VERSION ""

NS_ :

BS_:

BU_:

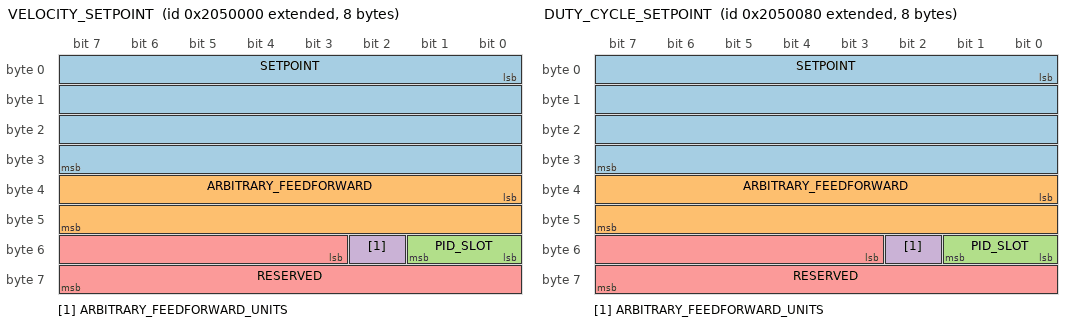
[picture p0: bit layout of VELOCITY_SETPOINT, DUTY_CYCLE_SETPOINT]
BO_ 2181365760 VELOCITY_SETPOINT: 8 Vector__XXX
 SG_ SETPOINT : 0|32@1- (1,0) [0|0] "" Vector__XXX
 SG_ ARBITRARY_FEEDFORWARD : 32|16@1- (0.0009765923,0) [0|0] "" Vector__XXX
 SG_ PID_SLOT : 48|2@1+ (1,0) [0|0] "" Vector__XXX
 SG_ ARBITRARY_FEEDFORWARD_UNITS : 50|1@1+ (1,0) [0|0] "" Vector__XXX
 SG_ RESERVED : 51|13@1+ (1,0) [0|0] "" Vector__XXX

CM_ BO_ 2181365760 "Sets the Control Type to Velocity and sets the target velocity";
CM_ SG_ 2181365760 SETPOINT "By default, the unit is RPM, but it can be changed implicitly using the Velocity Conversion Factor parameter";
CM_ SG_ 2181365760 ARBITRARY_FEEDFORWARD_UNITS "0: Voltage, 1: Duty Cycle (-1 to 1)";
SIG_VALTYPE_ 2181365760 SETPOINT : 1;

BO_ 2181365888 DUTY_CYCLE_SETPOINT: 8 Vector__XXX
 SG_ SETPOINT : 0|32@1- (1,0) [0|0] "" Vector__XXX
 SG_ ARBITRARY_FEEDFORWARD : 32|16@1- (0.0009765923,0) [0|0] "" Vector__XXX
 SG_ PID_SLOT : 48|2@1+ (1,0) [0|0] "" Vector__XXX
 SG_ ARBITRARY_FEEDFORWARD_UNITS : 50|1@1+ (1,0) [0|0] "" Vector__XXX
 SG_ RESERVED : 51|13@1+ (1,0) [0|0] "" Vector__XXX

CM_ BO_ 2181365888 "Sets the Control Type to Duty Cycle and sets the target duty cycle (from -1 to 1)";
CM_ SG_ 2181365888 ARBITRARY_FEEDFORWARD_UNITS "0: Voltage, 1: Duty Cycle (-1 to 1)";
SIG_VALTYPE_ 2181365888 SETPOINT : 1;

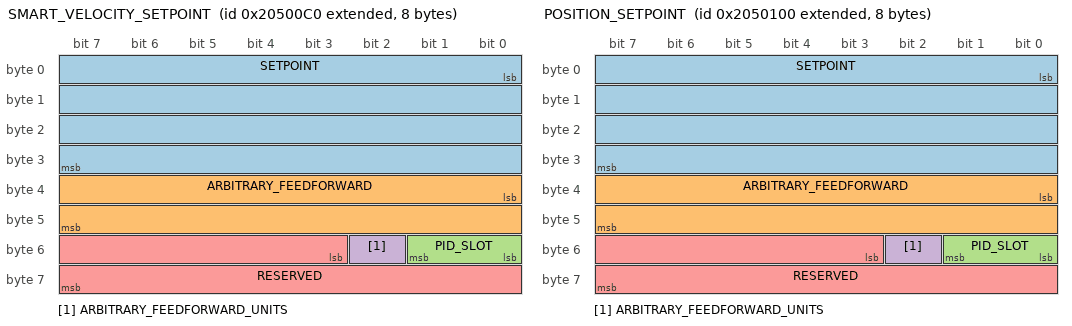
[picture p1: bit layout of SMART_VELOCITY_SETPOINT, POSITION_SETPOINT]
BO_ 2181365952 SMART_VELOCITY_SETPOINT: 8 Vector__XXX
 SG_ SETPOINT : 0|32@1- (1,0) [0|0] "" Vector__XXX
 SG_ ARBITRARY_FEEDFORWARD : 32|16@1- (0.0009765923,0) [0|0] "" Vector__XXX
 SG_ PID_SLOT : 48|2@1+ (1,0) [0|0] "" Vector__XXX
 SG_ ARBITRARY_FEEDFORWARD_UNITS : 50|1@1+ (1,0) [0|0] "" Vector__XXX
 SG_ RESERVED : 51|13@1+ (1,0) [0|0] "" Vector__XXX

CM_ BO_ 2181365952 "Sets the Control Type to Smart Velocity and sets the target velocity";
CM_ SG_ 2181365952 SETPOINT "By default, the unit is RPM, but it can be changed implicitly using the Velocity Conversion Factor parameter";
CM_ SG_ 2181365952 ARBITRARY_FEEDFORWARD_UNITS "0: Voltage, 1: Duty Cycle (-1 to 1)";
SIG_VALTYPE_ 2181365952 SETPOINT : 1;

BO_ 2181366016 POSITION_SETPOINT: 8 Vector__XXX
 SG_ SETPOINT : 0|32@1- (1,0) [0|0] "" Vector__XXX
 SG_ ARBITRARY_FEEDFORWARD : 32|16@1- (0.0009765923,0) [0|0] "" Vector__XXX
 SG_ PID_SLOT : 48|2@1+ (1,0) [0|0] "" Vector__XXX
 SG_ ARBITRARY_FEEDFORWARD_UNITS : 50|1@1+ (1,0) [0|0] "" Vector__XXX
 SG_ RESERVED : 51|13@1+ (1,0) [0|0] "" Vector__XXX

CM_ BO_ 2181366016 "Sets the Control Type to Position and sets the target position";
CM_ SG_ 2181366016 SETPOINT "By default, the unit is rotations, but it can be changed implicitly using the Position Conversion Factor parameter";
CM_ SG_ 2181366016 ARBITRARY_FEEDFORWARD_UNITS "0: Voltage, 1: Duty Cycle (-1 to 1)";
SIG_VALTYPE_ 2181366016 SETPOINT : 1;

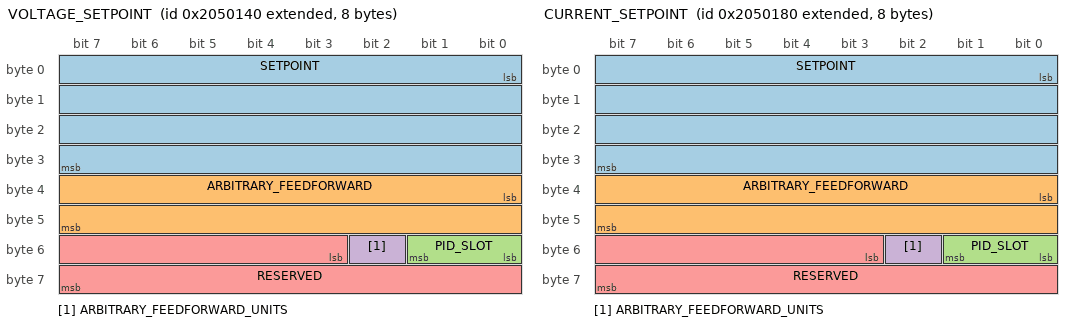
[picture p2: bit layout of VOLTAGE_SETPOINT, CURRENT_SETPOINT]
BO_ 2181366080 VOLTAGE_SETPOINT: 8 Vector__XXX
 SG_ SETPOINT : 0|32@1- (1,0) [0|0] "V" Vector__XXX
 SG_ ARBITRARY_FEEDFORWARD : 32|16@1- (0.0009765923,0) [0|0] "" Vector__XXX
 SG_ PID_SLOT : 48|2@1+ (1,0) [0|0] "" Vector__XXX
 SG_ ARBITRARY_FEEDFORWARD_UNITS : 50|1@1+ (1,0) [0|0] "" Vector__XXX
 SG_ RESERVED : 51|13@1+ (1,0) [0|0] "" Vector__XXX

CM_ BO_ 2181366080 "Sets the Control Type to Voltage and sets the target voltage";
CM_ SG_ 2181366080 ARBITRARY_FEEDFORWARD_UNITS "0: Voltage, 1: Duty Cycle (-1 to 1)";
SIG_VALTYPE_ 2181366080 SETPOINT : 1;

BO_ 2181366144 CURRENT_SETPOINT: 8 Vector__XXX
 SG_ SETPOINT : 0|32@1- (1,0) [0|0] "A" Vector__XXX
 SG_ ARBITRARY_FEEDFORWARD : 32|16@1- (0.0009765923,0) [0|0] "" Vector__XXX
 SG_ PID_SLOT : 48|2@1+ (1,0) [0|0] "" Vector__XXX
 SG_ ARBITRARY_FEEDFORWARD_UNITS : 50|1@1+ (1,0) [0|0] "" Vector__XXX
 SG_ RESERVED : 51|13@1+ (1,0) [0|0] "" Vector__XXX

CM_ BO_ 2181366144 "Sets the Control Type to Current and sets the target current";
CM_ SG_ 2181366144 ARBITRARY_FEEDFORWARD_UNITS "0: Voltage, 1: Duty Cycle (-1 to 1)";
SIG_VALTYPE_ 2181366144 SETPOINT : 1;

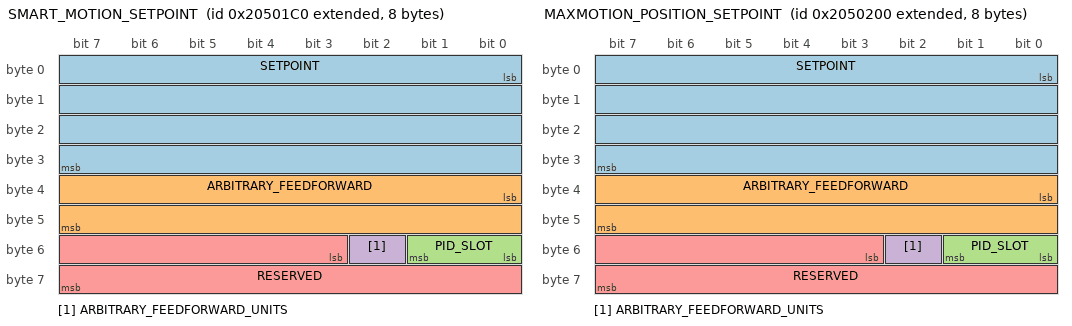
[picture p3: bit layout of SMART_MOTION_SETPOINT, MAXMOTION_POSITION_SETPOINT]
BO_ 2181366208 SMART_MOTION_SETPOINT: 8 Vector__XXX
 SG_ SETPOINT : 0|32@1- (1,0) [0|0] "" Vector__XXX
 SG_ ARBITRARY_FEEDFORWARD : 32|16@1- (0.0009765923,0) [0|0] "" Vector__XXX
 SG_ PID_SLOT : 48|2@1+ (1,0) [0|0] "" Vector__XXX
 SG_ ARBITRARY_FEEDFORWARD_UNITS : 50|1@1+ (1,0) [0|0] "" Vector__XXX
 SG_ RESERVED : 51|13@1+ (1,0) [0|0] "" Vector__XXX

CM_ BO_ 2181366208 "Sets the Control Type to Smart Motion and sets the target position";
CM_ SG_ 2181366208 SETPOINT "By default, the unit is rotations, but it can be changed implicitly using the Position Conversion Factor parameter";
CM_ SG_ 2181366208 ARBITRARY_FEEDFORWARD_UNITS "0: Voltage, 1: Duty Cycle (-1 to 1)";
SIG_VALTYPE_ 2181366208 SETPOINT : 1;

BO_ 2181366272 MAXMOTION_POSITION_SETPOINT: 8 Vector__XXX
 SG_ SETPOINT : 0|32@1- (1,0) [0|0] "" Vector__XXX
 SG_ ARBITRARY_FEEDFORWARD : 32|16@1- (0.0009765923,0) [0|0] "" Vector__XXX
 SG_ PID_SLOT : 48|2@1+ (1,0) [0|0] "" Vector__XXX
 SG_ ARBITRARY_FEEDFORWARD_UNITS : 50|1@1+ (1,0) [0|0] "" Vector__XXX
 SG_ RESERVED : 51|13@1+ (1,0) [0|0] "" Vector__XXX

CM_ BO_ 2181366272 "Sets the Control Type to MAXMotion Position Control and sets the target position";
CM_ SG_ 2181366272 SETPOINT "By default, the unit is rotations, but it can be changed implicitly using the Position Conversion Factor parameter";
CM_ SG_ 2181366272 ARBITRARY_FEEDFORWARD_UNITS "0: Voltage, 1: Duty Cycle (-1 to 1)";
SIG_VALTYPE_ 2181366272 SETPOINT : 1;

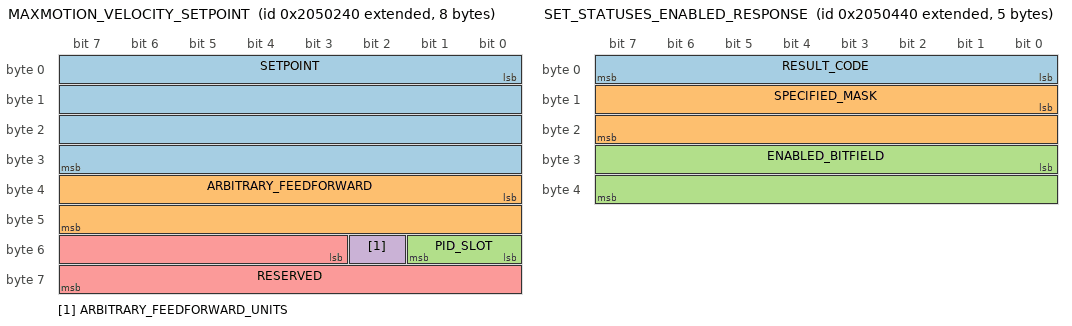
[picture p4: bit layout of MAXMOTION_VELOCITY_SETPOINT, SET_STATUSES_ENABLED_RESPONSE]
BO_ 2181366336 MAXMOTION_VELOCITY_SETPOINT: 8 Vector__XXX
 SG_ SETPOINT : 0|32@1- (1,0) [0|0] "" Vector__XXX
 SG_ ARBITRARY_FEEDFORWARD : 32|16@1- (0.0009765923,0) [0|0] "" Vector__XXX
 SG_ PID_SLOT : 48|2@1+ (1,0) [0|0] "" Vector__XXX
 SG_ ARBITRARY_FEEDFORWARD_UNITS : 50|1@1+ (1,0) [0|0] "" Vector__XXX
 SG_ RESERVED : 51|13@1+ (1,0) [0|0] "" Vector__XXX

CM_ BO_ 2181366336 "Sets the Control Type to MAXMotion Velocity Control and sets the target velocity";
CM_ SG_ 2181366336 SETPOINT "By default, the unit is RPM, but it can be changed implicitly using the Velocity Conversion Factor parameter";
CM_ SG_ 2181366336 ARBITRARY_FEEDFORWARD_UNITS "0: Voltage, 1: Duty Cycle (-1 to 1)";
SIG_VALTYPE_ 2181366336 SETPOINT : 1;

BO_ 2181366784 SET_STATUSES_ENABLED: 4 Vector__XXX
 SG_ MASK : 0|16@1+ (1,0) [0|0] "" Vector__XXX
 SG_ ENABLED_BITFIELD : 16|16@1+ (1,0) [0|0] "" Vector__XXX

CM_ BO_ 2181366784 "Enable or disable status frames. In response, a Set Statuses Enabled Response frame will be sent.";

BO_ 2181366848 SET_STATUSES_ENABLED_RESPONSE: 5 Vector__XXX
 SG_ RESULT_CODE : 0|8@1+ (1,0) [0|0] "" Vector__XXX
 SG_ SPECIFIED_MASK : 8|16@1+ (1,0) [0|0] "" Vector__XXX
 SG_ ENABLED_BITFIELD : 24|16@1+ (1,0) [0|0] "" Vector__XXX

CM_ BO_ 2181366848 "Response for a Set Statuses Enabled command";
CM_ SG_ 2181366848 RESULT_CODE "0 on success, 1 if any non-existent or unavailable frames were specified to be enabled";
CM_ SG_ 2181366848 SPECIFIED_MASK "Contains the mask specified in the Set Statuses Enabled command that triggered this response";
CM_ SG_ 2181366848 ENABLED_BITFIELD "Contains the full bitfield specifying which status frames are currently enabled, without any masking";

BO_ 2181367040 PERSIST_PARAMETERS_RESPONSE: 1 Vector__XXX
 SG_ RESULT_CODE : 0|8@1+ (1,0) [0|0] "" Vector__XXX

CM_ SG_ 2181367040 RESULT_CODE "0 on success";

BO_ 2181367104 RESET_SAFE_PARAMETERS: 2 Vector__XXX
 SG_ MAGIC_NUMBER : 0|16@1+ (1,0) [36292|36292] "" Vector__XXX

CM_ BO_ 2181367104 "Resets most writable parameters to their default values, except CAN ID, Motor Type, Idle Mode, PWM Input Deadband, and Duty Cycle Offset. In response, a Reset Safe Parameters Response frame is sent.";

BO_ 2181367168 RESET_SAFE_PARAMETERS_RESPONSE: 1 Vector__XXX
 SG_ RESULT_CODE : 0|8@1+ (1,0) [0|0] "" Vector__XXX

CM_ BO_ 2181367168 "Response for a Reset Safe Parameters command";
CM_ SG_ 2181367168 RESULT_CODE "0 on success";

BO_ 2181367232 COMPLETE_FACTORY_RESET: 2 Vector__XXX
 SG_ MAGIC_NUMBER : 0|16@1+ (1,0) [29741|29741] "" Vector__XXX

CM_ BO_ 2181367232 "Resets all writable parameters to default values, even CAN ID, Motor Type, Idle Mode, PWM Input Deadband, and Duty Cycle Offset. In response, a Complete Factory Reset Response frame is sent.";

BO_ 2181367296 COMPLETE_FACTORY_RESET_RESPONSE: 1 Vector__XXX
 SG_ RESULT_CODE : 0|8@1+ (1,0) [0|0] "" Vector__XXX

CM_ BO_ 2181367296 "Response for a Complete Factory Reset command";
CM_ SG_ 2181367296 RESULT_CODE "0 on success";

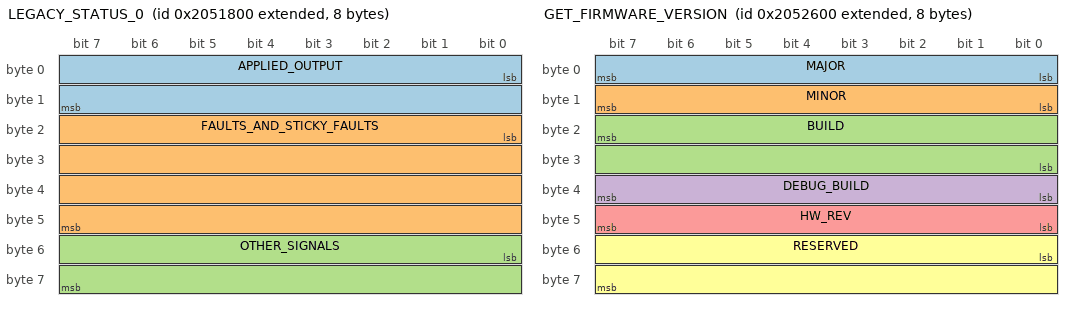
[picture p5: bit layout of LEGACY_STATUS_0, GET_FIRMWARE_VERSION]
BO_ 2181371904 LEGACY_STATUS_0: 8 Vector__XXX
 SG_ APPLIED_OUTPUT : 0|16@1+ (1,0) [0|0] "" Vector__XXX
 SG_ FAULTS_AND_STICKY_FAULTS : 16|32@1+ (1,0) [4294967295|4294967295] "" Vector__XXX
 SG_ OTHER_SIGNALS : 48|16@1+ (1,0) [0|0] "" Vector__XXX

CM_ BO_ 2181371904 "This frame exists purely to inform old software that is not aware of firmware version 25+ that the SPARK is present";
CM_ SG_ 2181371904 APPLIED_OUTPUT "Always 0 so that SPARKs running old firmware trying to follow this SPARK don't move";
CM_ SG_ 2181371904 FAULTS_AND_STICKY_FAULTS "Always has all faults set so that old software knows that something is wrong";
CM_ SG_ 2181371904 OTHER_SIGNALS "The other signals don't matter very much, and all get set to 0";

BO_ 2181372800 CLEAR_FAULTS: 0 Vector__XXX

BO_ 2181373312 IDENTIFY_UNIQUE_SPARK: 4 Vector__XXX
 SG_ UNIQUE_ID : 0|32@1+ (1,0) [0|0] "" Vector__XXX

CM_ BO_ 2181373312 "Makes the specified, single SPARK (even if there are multiple SPARKs that have the same CAN ID) temporarily perform a special blink pattern that will make it stand out";

BO_ 2181373376 IDENTIFY: 0 Vector__XXX

CM_ BO_ 2181373376 "Makes the SPARK temporarily perform a special blink pattern that will make it stand out. Use Identify Unique Device if there may be multiple SPARKs with the same CAN ID.";

BO_ 2181373952 NACK: 0 Vector__XXX

CM_ BO_ 2181373952 "As of SPARK MAX firmware 1.6.3, this is only used as a potential response to setting the CAN ID";

BO_ 2181374016 ACK: 0 Vector__XXX

CM_ BO_ 2181374016 "As of SPARK MAX firmware 1.6.3, this is only used as a potential response to setting the CAN ID";

BO_ 2181375168 LED_SYNC: 0 Vector__XXX

CM_ BO_ 2181375168 "Causes all SPARKs on the bus to synchronize their LED patterns";

BO_ 2181375296 SET_CAN_ID: 5 Vector__XXX
 SG_ UNIQUE_ID : 0|32@1+ (1,0) [0|0] "" Vector__XXX
 SG_ CAN_ID : 32|8@1+ (1,0) [0|63] "" Vector__XXX

CM_ BO_ 2181375296 "Allows changing the CAN ID when multiple devices on the bus currently have the same CAN ID. Under normal circumstances, the CAN ID parameter can be used.";

BO_ 2181375488 GET_FIRMWARE_VERSION: 8 Vector__XXX
 SG_ MAJOR : 0|8@1+ (1,0) [0|0] "" Vector__XXX
 SG_ MINOR : 8|8@1+ (1,0) [0|0] "" Vector__XXX
 SG_ BUILD : 23|16@0+ (1,0) [0|0] "" Vector__XXX
 SG_ DEBUG_BUILD : 32|8@1+ (1,0) [0|0] "" Vector__XXX
 SG_ HW_REV : 40|8@1+ (1,0) [0|0] "" Vector__XXX
 SG_ RESERVED : 48|16@1+ (1,0) [0|0] "" Vector__XXX

BO_ 2181375744 SWDL_DATA: 8 Vector__XXX
 SG_ DATA : 0|64@1+ (1,0) [0|0] "" Vector__XXX

CM_ BO_ 2181375744 "Broadcast from the host to all SPARKs in SWDL mode, containing a slice of firmware data";

BO_ 2181375808 SWDL_CHECKSUM: 8 Vector__XXX
 SG_ CHECKSUM : 0|64@1+ (1,0) [0|0] "" Vector__XXX

CM_ BO_ 2181375808 "Broadcast from the host to all SPARKs in SWDL mode, containing the checksum of the full firmware image that was just sent";

BO_ 2181375872 SWDL_RETRANSMIT: 0 Vector__XXX

CM_ BO_ 2181375872 "Sent by SPARK devices in response to receiving an SWDL Checksum frame that does not match the firmware data they received";

BO_ 2181376000 SET_PRIMARY_ENCODER_POSITION: 5 Vector__XXX
 SG_ POSITION : 0|32@1- (1,0) [0|0] "" Vector__XXX
 SG_ DATA_TYPE : 32|8@1+ (1,0) [3|3] "" Vector__XXX

CM_ SG_ 2181376000 POSITION "By default, the unit is rotations, but it can be changed implicitly using the Position Conversion Factor parameter";
SIG_VALTYPE_ 2181376000 POSITION : 1;

BO_ 2181376128 SET_I_ACCUMULATION: 5 Vector__XXX
 SG_ I_ACCUMULATION : 0|32@1- (1,0) [0|0] "" Vector__XXX
 SG_ DATA_TYPE : 32|8@1+ (1,0) [3|3] "" Vector__XXX

SIG_VALTYPE_ 2181376128 I_ACCUMULATION : 1;

BO_ 2181376192 SET_ANALOG_POSITION: 5 Vector__XXX
 SG_ POSITION : 0|32@1- (1,0) [0|0] "" Vector__XXX
 SG_ DATA_TYPE : 32|8@1+ (1,0) [3|3] "" Vector__XXX

CM_ SG_ 2181376192 POSITION "By default, the unit is rotations, but it can be changed implicitly using the Analog Position Conversion Factor parameter";
SIG_VALTYPE_ 2181376192 POSITION : 1;

BO_ 2181376256 SET_EXT_OR_ALT_ENCODER_POSITION: 5 Vector__XXX
 SG_ POSITION : 0|32@1- (1,0) [0|0] "" Vector__XXX
 SG_ DATA_TYPE : 32|8@1+ (1,0) [3|3] "" Vector__XXX

CM_ SG_ 2181376256 POSITION "By default, the unit is rotations, but it can be changed implicitly using the External/Alternate Encoder Position Conversion Factor parameter";
SIG_VALTYPE_ 2181376256 POSITION : 1;

BO_ 2181376320 SET_DUTY_CYCLE_POSITION: 5 Vector__XXX
 SG_ POSITION : 0|32@1- (1,0) [0|0] "" Vector__XXX
 SG_ DATA_TYPE : 32|8@1+ (1,0) [3|3] "" Vector__XXX

CM_ SG_ 2181376320 POSITION "By default, the unit is rotations, but it can be changed implicitly using the Duty Cycle Position Conversion Factor parameter";
SIG_VALTYPE_ 2181376320 POSITION : 1;

BO_ 2181377152 SECONDARY_HEARTBEAT: 8 Vector__XXX
 SG_ ENABLED_SPARKS_BITFIELD : 0|64@1+ (1,0) [0|0] "" Vector__XXX

CM_ BO_ 2181377152 "Heartbeat that allows enabling only specific SPARKs, but only gets respected when the SPARK is not locked to the Universal Heartbeat or Primary Heartbeat";

BO_ 2181377216 USB_ONLY_IDENTIFY: 0 Vector__XXX

CM_ BO_ 2181377216 "The response will only be sent if this command is received directly via USB. This has no relation to the normal Identify command, which displays an LED pattern.";

BO_ 2181377280 USB_ONLY_ENTER_DFU_BOOTLOADER: 2 Vector__XXX
 SG_ MAGIC_NUMBER : 0|16@1+ (1,0) [64069|64069] "" Vector__XXX

CM_ BO_ 2181377280 "Causes the device to reboot into the DFU bootloader if this command is received directly via USB";

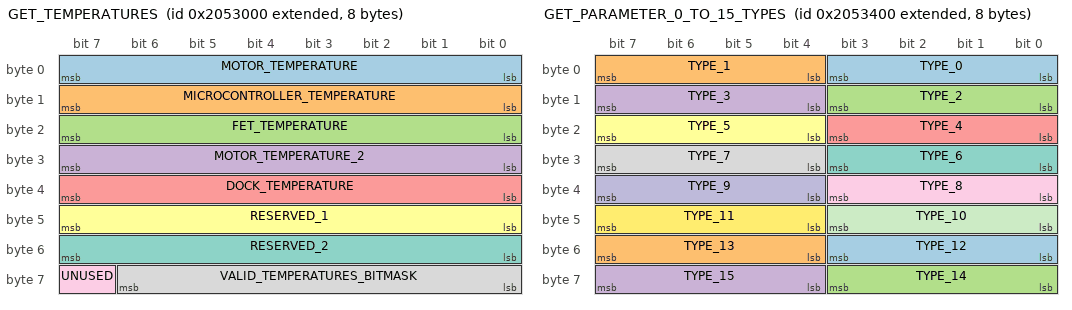
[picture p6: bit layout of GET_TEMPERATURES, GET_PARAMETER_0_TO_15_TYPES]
BO_ 2181378048 GET_TEMPERATURES: 8 Vector__XXX
 SG_ MOTOR_TEMPERATURE : 0|8@1+ (1,0) [0|0] "degC" Vector__XXX
 SG_ MICROCONTROLLER_TEMPERATURE : 8|8@1+ (1,0) [0|0] "degC" Vector__XXX
 SG_ FET_TEMPERATURE : 16|8@1+ (1,0) [0|0] "degC" Vector__XXX
 SG_ MOTOR_TEMPERATURE_2 : 24|8@1+ (1,0) [0|0] "degC" Vector__XXX
 SG_ DOCK_TEMPERATURE : 32|8@1+ (1,0) [0|0] "degC" Vector__XXX
 SG_ RESERVED_1 : 40|8@1+ (1,0) [0|0] "degC" Vector__XXX
 SG_ RESERVED_2 : 48|8@1+ (1,0) [0|0] "degC" Vector__XXX
 SG_ VALID_TEMPERATURES_BITMASK : 56|7@1+ (1,0) [0|0] "" Vector__XXX
 SG_ UNUSED : 63|1@1+ (1,0) [0|0] "" Vector__XXX

CM_ SG_ 2181378048 VALID_TEMPERATURES_BITMASK "Each bit corresponds to one of the 7 temperature fields";

BO_ 2181378368 GET_MOTOR_INTERFACE: 3 Vector__XXX
 SG_ MOTOR_INTERFACE : 0|16@1+ (1,0) [0|0] "" Vector__XXX
 SG_ PRIMARY_SENSOR_TYPE : 16|8@1+ (1,0) [0|0] "" Vector__XXX

CM_ SG_ 2181378368 MOTOR_INTERFACE "0: None, 1: SPARK Flex Dock / SPARK MAX, 2: SPARK Flex standard motor interface";
CM_ SG_ 2181378368 PRIMARY_SENSOR_TYPE "0: UVW, 1: Quadrature, 2: Quadrature (integrated)";

BO_ 2181379072 GET_PARAMETER_0_TO_15_TYPES: 8 Vector__XXX
 SG_ TYPE_0 : 0|4@1+ (1,0) [0|0] "" Vector__XXX
 SG_ TYPE_1 : 4|4@1+ (1,0) [0|0] "" Vector__XXX
 SG_ TYPE_2 : 8|4@1+ (1,0) [0|0] "" Vector__XXX
 SG_ TYPE_3 : 12|4@1+ (1,0) [0|0] "" Vector__XXX
 SG_ TYPE_4 : 16|4@1+ (1,0) [0|0] "" Vector__XXX
 SG_ TYPE_5 : 20|4@1+ (1,0) [0|0] "" Vector__XXX
 SG_ TYPE_6 : 24|4@1+ (1,0) [0|0] "" Vector__XXX
 SG_ TYPE_7 : 28|4@1+ (1,0) [0|0] "" Vector__XXX
 SG_ TYPE_8 : 32|4@1+ (1,0) [0|0] "" Vector__XXX
 SG_ TYPE_9 : 36|4@1+ (1,0) [0|0] "" Vector__XXX
 SG_ TYPE_10 : 40|4@1+ (1,0) [0|0] "" Vector__XXX
 SG_ TYPE_11 : 44|4@1+ (1,0) [0|0] "" Vector__XXX
 SG_ TYPE_12 : 48|4@1+ (1,0) [0|0] "" Vector__XXX
 SG_ TYPE_13 : 52|4@1+ (1,0) [0|0] "" Vector__XXX
 SG_ TYPE_14 : 56|4@1+ (1,0) [0|0] "" Vector__XXX
 SG_ TYPE_15 : 60|4@1+ (1,0) [0|0] "" Vector__XXX

CM_ BO_ 2181379072 "Get types of parameters 0 to 15";
CM_ SG_ 2181379072 TYPE_0 "0: Unused, 1: Int, 2: Uint, 3: Float, 4: Boolean";
CM_ SG_ 2181379072 TYPE_1 "0: Unused, 1: Int, 2: Uint, 3: Float, 4: Boolean";
CM_ SG_ 2181379072 TYPE_2 "0: Unused, 1: Int, 2: Uint, 3: Float, 4: Boolean";
CM_ SG_ 2181379072 TYPE_3 "0: Unused, 1: Int, 2: Uint, 3: Float, 4: Boolean";
CM_ SG_ 2181379072 TYPE_4 "0: Unused, 1: Int, 2: Uint, 3: Float, 4: Boolean";
CM_ SG_ 2181379072 TYPE_5 "0: Unused, 1: Int, 2: Uint, 3: Float, 4: Boolean";
CM_ SG_ 2181379072 TYPE_6 "0: Unused, 1: Int, 2: Uint, 3: Float, 4: Boolean";
CM_ SG_ 2181379072 TYPE_7 "0: Unused, 1: Int, 2: Uint, 3: Float, 4: Boolean";
CM_ SG_ 2181379072 TYPE_8 "0: Unused, 1: Int, 2: Uint, 3: Float, 4: Boolean";
CM_ SG_ 2181379072 TYPE_9 "0: Unused, 1: Int, 2: Uint, 3: Float, 4: Boolean";
CM_ SG_ 2181379072 TYPE_10 "0: Unused, 1: Int, 2: Uint, 3: Float, 4: Boolean";
CM_ SG_ 2181379072 TYPE_11 "0: Unused, 1: Int, 2: Uint, 3: Float, 4: Boolean";
CM_ SG_ 2181379072 TYPE_12 "0: Unused, 1: Int, 2: Uint, 3: Float, 4: Boolean";
CM_ SG_ 2181379072 TYPE_13 "0: Unused, 1: Int, 2: Uint, 3: Float, 4: Boolean";
CM_ SG_ 2181379072 TYPE_14 "0: Unused, 1: Int, 2: Uint, 3: Float, 4: Boolean";
CM_ SG_ 2181379072 TYPE_15 "0: Unused, 1: Int, 2: Uint, 3: Float, 4: Boolean";

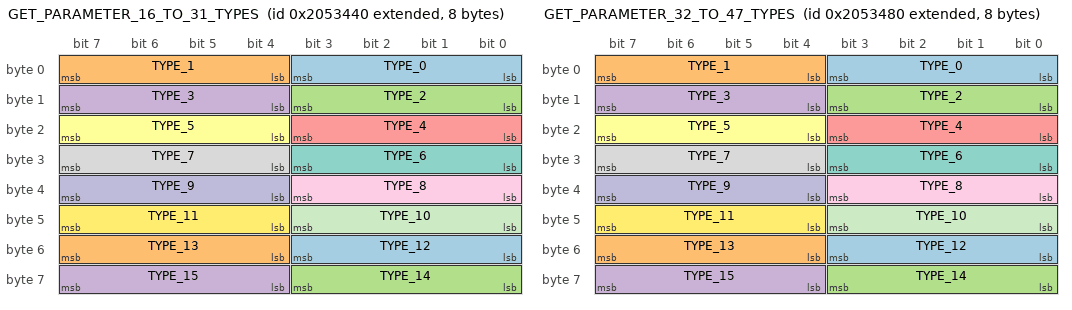
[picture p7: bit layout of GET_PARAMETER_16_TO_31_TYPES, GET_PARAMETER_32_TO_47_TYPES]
BO_ 2181379136 GET_PARAMETER_16_TO_31_TYPES: 8 Vector__XXX
 SG_ TYPE_0 : 0|4@1+ (1,0) [0|0] "" Vector__XXX
 SG_ TYPE_1 : 4|4@1+ (1,0) [0|0] "" Vector__XXX
 SG_ TYPE_2 : 8|4@1+ (1,0) [0|0] "" Vector__XXX
 SG_ TYPE_3 : 12|4@1+ (1,0) [0|0] "" Vector__XXX
 SG_ TYPE_4 : 16|4@1+ (1,0) [0|0] "" Vector__XXX
 SG_ TYPE_5 : 20|4@1+ (1,0) [0|0] "" Vector__XXX
 SG_ TYPE_6 : 24|4@1+ (1,0) [0|0] "" Vector__XXX
 SG_ TYPE_7 : 28|4@1+ (1,0) [0|0] "" Vector__XXX
 SG_ TYPE_8 : 32|4@1+ (1,0) [0|0] "" Vector__XXX
 SG_ TYPE_9 : 36|4@1+ (1,0) [0|0] "" Vector__XXX
 SG_ TYPE_10 : 40|4@1+ (1,0) [0|0] "" Vector__XXX
 SG_ TYPE_11 : 44|4@1+ (1,0) [0|0] "" Vector__XXX
 SG_ TYPE_12 : 48|4@1+ (1,0) [0|0] "" Vector__XXX
 SG_ TYPE_13 : 52|4@1+ (1,0) [0|0] "" Vector__XXX
 SG_ TYPE_14 : 56|4@1+ (1,0) [0|0] "" Vector__XXX
 SG_ TYPE_15 : 60|4@1+ (1,0) [0|0] "" Vector__XXX

CM_ BO_ 2181379136 "Get types of parameters 16 to 31";
CM_ SG_ 2181379136 TYPE_0 "0: Unused, 1: Int, 2: Uint, 3: Float, 4: Boolean";
CM_ SG_ 2181379136 TYPE_1 "0: Unused, 1: Int, 2: Uint, 3: Float, 4: Boolean";
CM_ SG_ 2181379136 TYPE_2 "0: Unused, 1: Int, 2: Uint, 3: Float, 4: Boolean";
CM_ SG_ 2181379136 TYPE_3 "0: Unused, 1: Int, 2: Uint, 3: Float, 4: Boolean";
CM_ SG_ 2181379136 TYPE_4 "0: Unused, 1: Int, 2: Uint, 3: Float, 4: Boolean";
CM_ SG_ 2181379136 TYPE_5 "0: Unused, 1: Int, 2: Uint, 3: Float, 4: Boolean";
CM_ SG_ 2181379136 TYPE_6 "0: Unused, 1: Int, 2: Uint, 3: Float, 4: Boolean";
CM_ SG_ 2181379136 TYPE_7 "0: Unused, 1: Int, 2: Uint, 3: Float, 4: Boolean";
CM_ SG_ 2181379136 TYPE_8 "0: Unused, 1: Int, 2: Uint, 3: Float, 4: Boolean";
CM_ SG_ 2181379136 TYPE_9 "0: Unused, 1: Int, 2: Uint, 3: Float, 4: Boolean";
CM_ SG_ 2181379136 TYPE_10 "0: Unused, 1: Int, 2: Uint, 3: Float, 4: Boolean";
CM_ SG_ 2181379136 TYPE_11 "0: Unused, 1: Int, 2: Uint, 3: Float, 4: Boolean";
CM_ SG_ 2181379136 TYPE_12 "0: Unused, 1: Int, 2: Uint, 3: Float, 4: Boolean";
CM_ SG_ 2181379136 TYPE_13 "0: Unused, 1: Int, 2: Uint, 3: Float, 4: Boolean";
CM_ SG_ 2181379136 TYPE_14 "0: Unused, 1: Int, 2: Uint, 3: Float, 4: Boolean";
CM_ SG_ 2181379136 TYPE_15 "0: Unused, 1: Int, 2: Uint, 3: Float, 4: Boolean";

BO_ 2181379200 GET_PARAMETER_32_TO_47_TYPES: 8 Vector__XXX
 SG_ TYPE_0 : 0|4@1+ (1,0) [0|0] "" Vector__XXX
 SG_ TYPE_1 : 4|4@1+ (1,0) [0|0] "" Vector__XXX
 SG_ TYPE_2 : 8|4@1+ (1,0) [0|0] "" Vector__XXX
 SG_ TYPE_3 : 12|4@1+ (1,0) [0|0] "" Vector__XXX
 SG_ TYPE_4 : 16|4@1+ (1,0) [0|0] "" Vector__XXX
 SG_ TYPE_5 : 20|4@1+ (1,0) [0|0] "" Vector__XXX
 SG_ TYPE_6 : 24|4@1+ (1,0) [0|0] "" Vector__XXX
 SG_ TYPE_7 : 28|4@1+ (1,0) [0|0] "" Vector__XXX
 SG_ TYPE_8 : 32|4@1+ (1,0) [0|0] "" Vector__XXX
 SG_ TYPE_9 : 36|4@1+ (1,0) [0|0] "" Vector__XXX
 SG_ TYPE_10 : 40|4@1+ (1,0) [0|0] "" Vector__XXX
 SG_ TYPE_11 : 44|4@1+ (1,0) [0|0] "" Vector__XXX
 SG_ TYPE_12 : 48|4@1+ (1,0) [0|0] "" Vector__XXX
 SG_ TYPE_13 : 52|4@1+ (1,0) [0|0] "" Vector__XXX
 SG_ TYPE_14 : 56|4@1+ (1,0) [0|0] "" Vector__XXX
 SG_ TYPE_15 : 60|4@1+ (1,0) [0|0] "" Vector__XXX

CM_ BO_ 2181379200 "Get types of parameters 32 to 47";
CM_ SG_ 2181379200 TYPE_0 "0: Unused, 1: Int, 2: Uint, 3: Float, 4: Boolean";
CM_ SG_ 2181379200 TYPE_1 "0: Unused, 1: Int, 2: Uint, 3: Float, 4: Boolean";
CM_ SG_ 2181379200 TYPE_2 "0: Unused, 1: Int, 2: Uint, 3: Float, 4: Boolean";
CM_ SG_ 2181379200 TYPE_3 "0: Unused, 1: Int, 2: Uint, 3: Float, 4: Boolean";
CM_ SG_ 2181379200 TYPE_4 "0: Unused, 1: Int, 2: Uint, 3: Float, 4: Boolean";
CM_ SG_ 2181379200 TYPE_5 "0: Unused, 1: Int, 2: Uint, 3: Float, 4: Boolean";
CM_ SG_ 2181379200 TYPE_6 "0: Unused, 1: Int, 2: Uint, 3: Float, 4: Boolean";
CM_ SG_ 2181379200 TYPE_7 "0: Unused, 1: Int, 2: Uint, 3: Float, 4: Boolean";
CM_ SG_ 2181379200 TYPE_8 "0: Unused, 1: Int, 2: Uint, 3: Float, 4: Boolean";
CM_ SG_ 2181379200 TYPE_9 "0: Unused, 1: Int, 2: Uint, 3: Float, 4: Boolean";
CM_ SG_ 2181379200 TYPE_10 "0: Unused, 1: Int, 2: Uint, 3: Float, 4: Boolean";
CM_ SG_ 2181379200 TYPE_11 "0: Unused, 1: Int, 2: Uint, 3: Float, 4: Boolean";
CM_ SG_ 2181379200 TYPE_12 "0: Unused, 1: Int, 2: Uint, 3: Float, 4: Boolean";
CM_ SG_ 2181379200 TYPE_13 "0: Unused, 1: Int, 2: Uint, 3: Float, 4: Boolean";
CM_ SG_ 2181379200 TYPE_14 "0: Unused, 1: Int, 2: Uint, 3: Float, 4: Boolean";
CM_ SG_ 2181379200 TYPE_15 "0: Unused, 1: Int, 2: Uint, 3: Float, 4: Boolean";

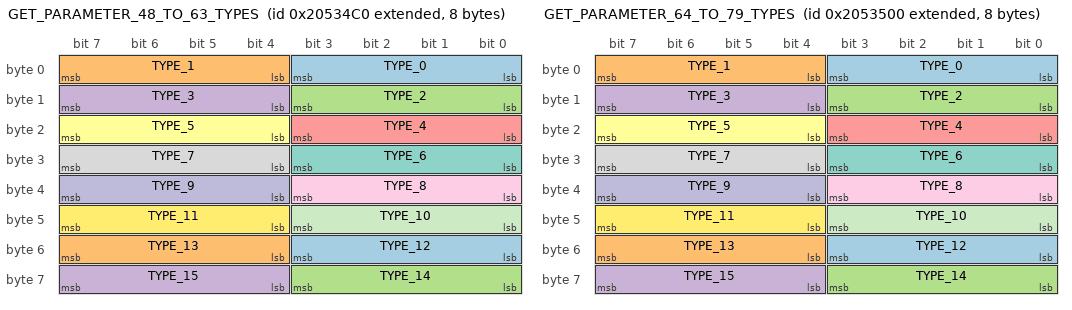
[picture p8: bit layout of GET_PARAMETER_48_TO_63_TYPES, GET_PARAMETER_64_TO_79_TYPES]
BO_ 2181379264 GET_PARAMETER_48_TO_63_TYPES: 8 Vector__XXX
 SG_ TYPE_0 : 0|4@1+ (1,0) [0|0] "" Vector__XXX
 SG_ TYPE_1 : 4|4@1+ (1,0) [0|0] "" Vector__XXX
 SG_ TYPE_2 : 8|4@1+ (1,0) [0|0] "" Vector__XXX
 SG_ TYPE_3 : 12|4@1+ (1,0) [0|0] "" Vector__XXX
 SG_ TYPE_4 : 16|4@1+ (1,0) [0|0] "" Vector__XXX
 SG_ TYPE_5 : 20|4@1+ (1,0) [0|0] "" Vector__XXX
 SG_ TYPE_6 : 24|4@1+ (1,0) [0|0] "" Vector__XXX
 SG_ TYPE_7 : 28|4@1+ (1,0) [0|0] "" Vector__XXX
 SG_ TYPE_8 : 32|4@1+ (1,0) [0|0] "" Vector__XXX
 SG_ TYPE_9 : 36|4@1+ (1,0) [0|0] "" Vector__XXX
 SG_ TYPE_10 : 40|4@1+ (1,0) [0|0] "" Vector__XXX
 SG_ TYPE_11 : 44|4@1+ (1,0) [0|0] "" Vector__XXX
 SG_ TYPE_12 : 48|4@1+ (1,0) [0|0] "" Vector__XXX
 SG_ TYPE_13 : 52|4@1+ (1,0) [0|0] "" Vector__XXX
 SG_ TYPE_14 : 56|4@1+ (1,0) [0|0] "" Vector__XXX
 SG_ TYPE_15 : 60|4@1+ (1,0) [0|0] "" Vector__XXX

CM_ BO_ 2181379264 "Get types of parameters 48 to 63";
CM_ SG_ 2181379264 TYPE_0 "0: Unused, 1: Int, 2: Uint, 3: Float, 4: Boolean";
CM_ SG_ 2181379264 TYPE_1 "0: Unused, 1: Int, 2: Uint, 3: Float, 4: Boolean";
CM_ SG_ 2181379264 TYPE_2 "0: Unused, 1: Int, 2: Uint, 3: Float, 4: Boolean";
CM_ SG_ 2181379264 TYPE_3 "0: Unused, 1: Int, 2: Uint, 3: Float, 4: Boolean";
CM_ SG_ 2181379264 TYPE_4 "0: Unused, 1: Int, 2: Uint, 3: Float, 4: Boolean";
CM_ SG_ 2181379264 TYPE_5 "0: Unused, 1: Int, 2: Uint, 3: Float, 4: Boolean";
CM_ SG_ 2181379264 TYPE_6 "0: Unused, 1: Int, 2: Uint, 3: Float, 4: Boolean";
CM_ SG_ 2181379264 TYPE_7 "0: Unused, 1: Int, 2: Uint, 3: Float, 4: Boolean";
CM_ SG_ 2181379264 TYPE_8 "0: Unused, 1: Int, 2: Uint, 3: Float, 4: Boolean";
CM_ SG_ 2181379264 TYPE_9 "0: Unused, 1: Int, 2: Uint, 3: Float, 4: Boolean";
CM_ SG_ 2181379264 TYPE_10 "0: Unused, 1: Int, 2: Uint, 3: Float, 4: Boolean";
CM_ SG_ 2181379264 TYPE_11 "0: Unused, 1: Int, 2: Uint, 3: Float, 4: Boolean";
CM_ SG_ 2181379264 TYPE_12 "0: Unused, 1: Int, 2: Uint, 3: Float, 4: Boolean";
CM_ SG_ 2181379264 TYPE_13 "0: Unused, 1: Int, 2: Uint, 3: Float, 4: Boolean";
CM_ SG_ 2181379264 TYPE_14 "0: Unused, 1: Int, 2: Uint, 3: Float, 4: Boolean";
CM_ SG_ 2181379264 TYPE_15 "0: Unused, 1: Int, 2: Uint, 3: Float, 4: Boolean";

BO_ 2181379328 GET_PARAMETER_64_TO_79_TYPES: 8 Vector__XXX
 SG_ TYPE_0 : 0|4@1+ (1,0) [0|0] "" Vector__XXX
 SG_ TYPE_1 : 4|4@1+ (1,0) [0|0] "" Vector__XXX
 SG_ TYPE_2 : 8|4@1+ (1,0) [0|0] "" Vector__XXX
 SG_ TYPE_3 : 12|4@1+ (1,0) [0|0] "" Vector__XXX
 SG_ TYPE_4 : 16|4@1+ (1,0) [0|0] "" Vector__XXX
 SG_ TYPE_5 : 20|4@1+ (1,0) [0|0] "" Vector__XXX
 SG_ TYPE_6 : 24|4@1+ (1,0) [0|0] "" Vector__XXX
 SG_ TYPE_7 : 28|4@1+ (1,0) [0|0] "" Vector__XXX
 SG_ TYPE_8 : 32|4@1+ (1,0) [0|0] "" Vector__XXX
 SG_ TYPE_9 : 36|4@1+ (1,0) [0|0] "" Vector__XXX
 SG_ TYPE_10 : 40|4@1+ (1,0) [0|0] "" Vector__XXX
 SG_ TYPE_11 : 44|4@1+ (1,0) [0|0] "" Vector__XXX
 SG_ TYPE_12 : 48|4@1+ (1,0) [0|0] "" Vector__XXX
 SG_ TYPE_13 : 52|4@1+ (1,0) [0|0] "" Vector__XXX
 SG_ TYPE_14 : 56|4@1+ (1,0) [0|0] "" Vector__XXX
 SG_ TYPE_15 : 60|4@1+ (1,0) [0|0] "" Vector__XXX

CM_ BO_ 2181379328 "Get types of parameters 64 to 79";
CM_ SG_ 2181379328 TYPE_0 "0: Unused, 1: Int, 2: Uint, 3: Float, 4: Boolean";
CM_ SG_ 2181379328 TYPE_1 "0: Unused, 1: Int, 2: Uint, 3: Float, 4: Boolean";
CM_ SG_ 2181379328 TYPE_2 "0: Unused, 1: Int, 2: Uint, 3: Float, 4: Boolean";
CM_ SG_ 2181379328 TYPE_3 "0: Unused, 1: Int, 2: Uint, 3: Float, 4: Boolean";
CM_ SG_ 2181379328 TYPE_4 "0: Unused, 1: Int, 2: Uint, 3: Float, 4: Boolean";
CM_ SG_ 2181379328 TYPE_5 "0: Unused, 1: Int, 2: Uint, 3: Float, 4: Boolean";
CM_ SG_ 2181379328 TYPE_6 "0: Unused, 1: Int, 2: Uint, 3: Float, 4: Boolean";
CM_ SG_ 2181379328 TYPE_7 "0: Unused, 1: Int, 2: Uint, 3: Float, 4: Boolean";
CM_ SG_ 2181379328 TYPE_8 "0: Unused, 1: Int, 2: Uint, 3: Float, 4: Boolean";
CM_ SG_ 2181379328 TYPE_9 "0: Unused, 1: Int, 2: Uint, 3: Float, 4: Boolean";
CM_ SG_ 2181379328 TYPE_10 "0: Unused, 1: Int, 2: Uint, 3: Float, 4: Boolean";
CM_ SG_ 2181379328 TYPE_11 "0: Unused, 1: Int, 2: Uint, 3: Float, 4: Boolean";
CM_ SG_ 2181379328 TYPE_12 "0: Unused, 1: Int, 2: Uint, 3: Float, 4: Boolean";
CM_ SG_ 2181379328 TYPE_13 "0: Unused, 1: Int, 2: Uint, 3: Float, 4: Boolean";
CM_ SG_ 2181379328 TYPE_14 "0: Unused, 1: Int, 2: Uint, 3: Float, 4: Boolean";
CM_ SG_ 2181379328 TYPE_15 "0: Unused, 1: Int, 2: Uint, 3: Float, 4: Boolean";

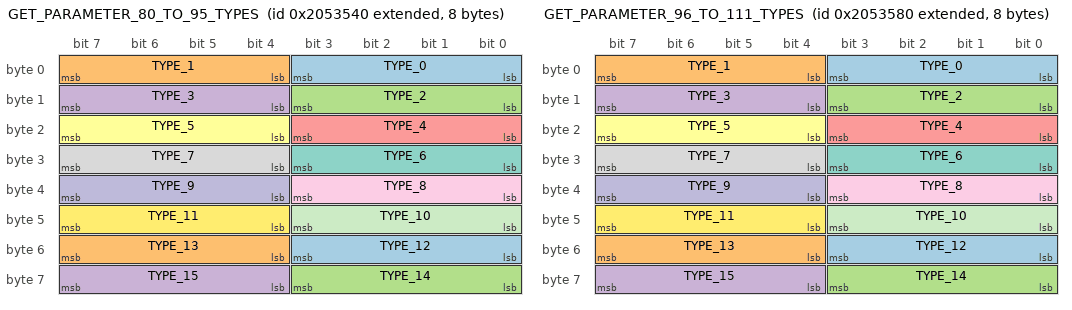
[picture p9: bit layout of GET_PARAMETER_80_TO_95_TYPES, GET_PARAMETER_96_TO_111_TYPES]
BO_ 2181379392 GET_PARAMETER_80_TO_95_TYPES: 8 Vector__XXX
 SG_ TYPE_0 : 0|4@1+ (1,0) [0|0] "" Vector__XXX
 SG_ TYPE_1 : 4|4@1+ (1,0) [0|0] "" Vector__XXX
 SG_ TYPE_2 : 8|4@1+ (1,0) [0|0] "" Vector__XXX
 SG_ TYPE_3 : 12|4@1+ (1,0) [0|0] "" Vector__XXX
 SG_ TYPE_4 : 16|4@1+ (1,0) [0|0] "" Vector__XXX
 SG_ TYPE_5 : 20|4@1+ (1,0) [0|0] "" Vector__XXX
 SG_ TYPE_6 : 24|4@1+ (1,0) [0|0] "" Vector__XXX
 SG_ TYPE_7 : 28|4@1+ (1,0) [0|0] "" Vector__XXX
 SG_ TYPE_8 : 32|4@1+ (1,0) [0|0] "" Vector__XXX
 SG_ TYPE_9 : 36|4@1+ (1,0) [0|0] "" Vector__XXX
 SG_ TYPE_10 : 40|4@1+ (1,0) [0|0] "" Vector__XXX
 SG_ TYPE_11 : 44|4@1+ (1,0) [0|0] "" Vector__XXX
 SG_ TYPE_12 : 48|4@1+ (1,0) [0|0] "" Vector__XXX
 SG_ TYPE_13 : 52|4@1+ (1,0) [0|0] "" Vector__XXX
 SG_ TYPE_14 : 56|4@1+ (1,0) [0|0] "" Vector__XXX
 SG_ TYPE_15 : 60|4@1+ (1,0) [0|0] "" Vector__XXX

CM_ BO_ 2181379392 "Get types of parameters 80 to 95";
CM_ SG_ 2181379392 TYPE_0 "0: Unused, 1: Int, 2: Uint, 3: Float, 4: Boolean";
CM_ SG_ 2181379392 TYPE_1 "0: Unused, 1: Int, 2: Uint, 3: Float, 4: Boolean";
CM_ SG_ 2181379392 TYPE_2 "0: Unused, 1: Int, 2: Uint, 3: Float, 4: Boolean";
CM_ SG_ 2181379392 TYPE_3 "0: Unused, 1: Int, 2: Uint, 3: Float, 4: Boolean";
CM_ SG_ 2181379392 TYPE_4 "0: Unused, 1: Int, 2: Uint, 3: Float, 4: Boolean";
CM_ SG_ 2181379392 TYPE_5 "0: Unused, 1: Int, 2: Uint, 3: Float, 4: Boolean";
CM_ SG_ 2181379392 TYPE_6 "0: Unused, 1: Int, 2: Uint, 3: Float, 4: Boolean";
CM_ SG_ 2181379392 TYPE_7 "0: Unused, 1: Int, 2: Uint, 3: Float, 4: Boolean";
CM_ SG_ 2181379392 TYPE_8 "0: Unused, 1: Int, 2: Uint, 3: Float, 4: Boolean";
CM_ SG_ 2181379392 TYPE_9 "0: Unused, 1: Int, 2: Uint, 3: Float, 4: Boolean";
CM_ SG_ 2181379392 TYPE_10 "0: Unused, 1: Int, 2: Uint, 3: Float, 4: Boolean";
CM_ SG_ 2181379392 TYPE_11 "0: Unused, 1: Int, 2: Uint, 3: Float, 4: Boolean";
CM_ SG_ 2181379392 TYPE_12 "0: Unused, 1: Int, 2: Uint, 3: Float, 4: Boolean";
CM_ SG_ 2181379392 TYPE_13 "0: Unused, 1: Int, 2: Uint, 3: Float, 4: Boolean";
CM_ SG_ 2181379392 TYPE_14 "0: Unused, 1: Int, 2: Uint, 3: Float, 4: Boolean";
CM_ SG_ 2181379392 TYPE_15 "0: Unused, 1: Int, 2: Uint, 3: Float, 4: Boolean";

BO_ 2181379456 GET_PARAMETER_96_TO_111_TYPES: 8 Vector__XXX
 SG_ TYPE_0 : 0|4@1+ (1,0) [0|0] "" Vector__XXX
 SG_ TYPE_1 : 4|4@1+ (1,0) [0|0] "" Vector__XXX
 SG_ TYPE_2 : 8|4@1+ (1,0) [0|0] "" Vector__XXX
 SG_ TYPE_3 : 12|4@1+ (1,0) [0|0] "" Vector__XXX
 SG_ TYPE_4 : 16|4@1+ (1,0) [0|0] "" Vector__XXX
 SG_ TYPE_5 : 20|4@1+ (1,0) [0|0] "" Vector__XXX
 SG_ TYPE_6 : 24|4@1+ (1,0) [0|0] "" Vector__XXX
 SG_ TYPE_7 : 28|4@1+ (1,0) [0|0] "" Vector__XXX
 SG_ TYPE_8 : 32|4@1+ (1,0) [0|0] "" Vector__XXX
 SG_ TYPE_9 : 36|4@1+ (1,0) [0|0] "" Vector__XXX
 SG_ TYPE_10 : 40|4@1+ (1,0) [0|0] "" Vector__XXX
 SG_ TYPE_11 : 44|4@1+ (1,0) [0|0] "" Vector__XXX
 SG_ TYPE_12 : 48|4@1+ (1,0) [0|0] "" Vector__XXX
 SG_ TYPE_13 : 52|4@1+ (1,0) [0|0] "" Vector__XXX
 SG_ TYPE_14 : 56|4@1+ (1,0) [0|0] "" Vector__XXX
 SG_ TYPE_15 : 60|4@1+ (1,0) [0|0] "" Vector__XXX

CM_ BO_ 2181379456 "Get types of parameters 96 to 111";
CM_ SG_ 2181379456 TYPE_0 "0: Unused, 1: Int, 2: Uint, 3: Float, 4: Boolean";
CM_ SG_ 2181379456 TYPE_1 "0: Unused, 1: Int, 2: Uint, 3: Float, 4: Boolean";
CM_ SG_ 2181379456 TYPE_2 "0: Unused, 1: Int, 2: Uint, 3: Float, 4: Boolean";
CM_ SG_ 2181379456 TYPE_3 "0: Unused, 1: Int, 2: Uint, 3: Float, 4: Boolean";
CM_ SG_ 2181379456 TYPE_4 "0: Unused, 1: Int, 2: Uint, 3: Float, 4: Boolean";
CM_ SG_ 2181379456 TYPE_5 "0: Unused, 1: Int, 2: Uint, 3: Float, 4: Boolean";
CM_ SG_ 2181379456 TYPE_6 "0: Unused, 1: Int, 2: Uint, 3: Float, 4: Boolean";
CM_ SG_ 2181379456 TYPE_7 "0: Unused, 1: Int, 2: Uint, 3: Float, 4: Boolean";
CM_ SG_ 2181379456 TYPE_8 "0: Unused, 1: Int, 2: Uint, 3: Float, 4: Boolean";
CM_ SG_ 2181379456 TYPE_9 "0: Unused, 1: Int, 2: Uint, 3: Float, 4: Boolean";
CM_ SG_ 2181379456 TYPE_10 "0: Unused, 1: Int, 2: Uint, 3: Float, 4: Boolean";
CM_ SG_ 2181379456 TYPE_11 "0: Unused, 1: Int, 2: Uint, 3: Float, 4: Boolean";
CM_ SG_ 2181379456 TYPE_12 "0: Unused, 1: Int, 2: Uint, 3: Float, 4: Boolean";
CM_ SG_ 2181379456 TYPE_13 "0: Unused, 1: Int, 2: Uint, 3: Float, 4: Boolean";
CM_ SG_ 2181379456 TYPE_14 "0: Unused, 1: Int, 2: Uint, 3: Float, 4: Boolean";
CM_ SG_ 2181379456 TYPE_15 "0: Unused, 1: Int, 2: Uint, 3: Float, 4: Boolean";

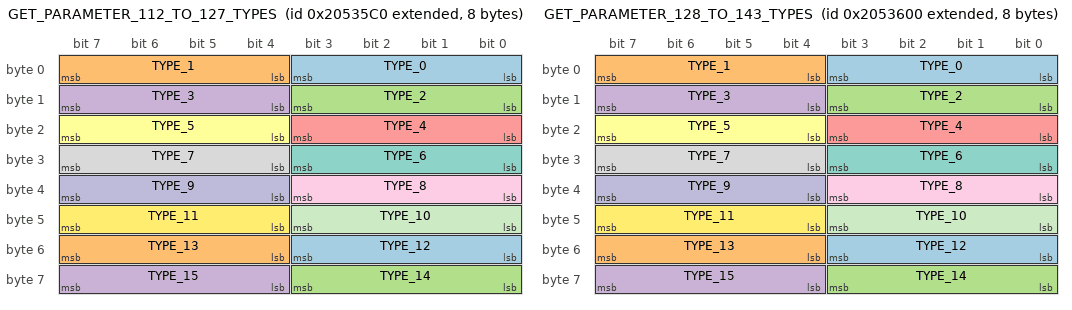
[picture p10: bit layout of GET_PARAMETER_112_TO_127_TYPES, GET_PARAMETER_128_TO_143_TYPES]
BO_ 2181379520 GET_PARAMETER_112_TO_127_TYPES: 8 Vector__XXX
 SG_ TYPE_0 : 0|4@1+ (1,0) [0|0] "" Vector__XXX
 SG_ TYPE_1 : 4|4@1+ (1,0) [0|0] "" Vector__XXX
 SG_ TYPE_2 : 8|4@1+ (1,0) [0|0] "" Vector__XXX
 SG_ TYPE_3 : 12|4@1+ (1,0) [0|0] "" Vector__XXX
 SG_ TYPE_4 : 16|4@1+ (1,0) [0|0] "" Vector__XXX
 SG_ TYPE_5 : 20|4@1+ (1,0) [0|0] "" Vector__XXX
 SG_ TYPE_6 : 24|4@1+ (1,0) [0|0] "" Vector__XXX
 SG_ TYPE_7 : 28|4@1+ (1,0) [0|0] "" Vector__XXX
 SG_ TYPE_8 : 32|4@1+ (1,0) [0|0] "" Vector__XXX
 SG_ TYPE_9 : 36|4@1+ (1,0) [0|0] "" Vector__XXX
 SG_ TYPE_10 : 40|4@1+ (1,0) [0|0] "" Vector__XXX
 SG_ TYPE_11 : 44|4@1+ (1,0) [0|0] "" Vector__XXX
 SG_ TYPE_12 : 48|4@1+ (1,0) [0|0] "" Vector__XXX
 SG_ TYPE_13 : 52|4@1+ (1,0) [0|0] "" Vector__XXX
 SG_ TYPE_14 : 56|4@1+ (1,0) [0|0] "" Vector__XXX
 SG_ TYPE_15 : 60|4@1+ (1,0) [0|0] "" Vector__XXX

CM_ BO_ 2181379520 "Get types of parameters 112 to 127";
CM_ SG_ 2181379520 TYPE_0 "0: Unused, 1: Int, 2: Uint, 3: Float, 4: Boolean";
CM_ SG_ 2181379520 TYPE_1 "0: Unused, 1: Int, 2: Uint, 3: Float, 4: Boolean";
CM_ SG_ 2181379520 TYPE_2 "0: Unused, 1: Int, 2: Uint, 3: Float, 4: Boolean";
CM_ SG_ 2181379520 TYPE_3 "0: Unused, 1: Int, 2: Uint, 3: Float, 4: Boolean";
CM_ SG_ 2181379520 TYPE_4 "0: Unused, 1: Int, 2: Uint, 3: Float, 4: Boolean";
CM_ SG_ 2181379520 TYPE_5 "0: Unused, 1: Int, 2: Uint, 3: Float, 4: Boolean";
CM_ SG_ 2181379520 TYPE_6 "0: Unused, 1: Int, 2: Uint, 3: Float, 4: Boolean";
CM_ SG_ 2181379520 TYPE_7 "0: Unused, 1: Int, 2: Uint, 3: Float, 4: Boolean";
CM_ SG_ 2181379520 TYPE_8 "0: Unused, 1: Int, 2: Uint, 3: Float, 4: Boolean";
CM_ SG_ 2181379520 TYPE_9 "0: Unused, 1: Int, 2: Uint, 3: Float, 4: Boolean";
CM_ SG_ 2181379520 TYPE_10 "0: Unused, 1: Int, 2: Uint, 3: Float, 4: Boolean";
CM_ SG_ 2181379520 TYPE_11 "0: Unused, 1: Int, 2: Uint, 3: Float, 4: Boolean";
CM_ SG_ 2181379520 TYPE_12 "0: Unused, 1: Int, 2: Uint, 3: Float, 4: Boolean";
CM_ SG_ 2181379520 TYPE_13 "0: Unused, 1: Int, 2: Uint, 3: Float, 4: Boolean";
CM_ SG_ 2181379520 TYPE_14 "0: Unused, 1: Int, 2: Uint, 3: Float, 4: Boolean";
CM_ SG_ 2181379520 TYPE_15 "0: Unused, 1: Int, 2: Uint, 3: Float, 4: Boolean";

BO_ 2181379584 GET_PARAMETER_128_TO_143_TYPES: 8 Vector__XXX
 SG_ TYPE_0 : 0|4@1+ (1,0) [0|0] "" Vector__XXX
 SG_ TYPE_1 : 4|4@1+ (1,0) [0|0] "" Vector__XXX
 SG_ TYPE_2 : 8|4@1+ (1,0) [0|0] "" Vector__XXX
 SG_ TYPE_3 : 12|4@1+ (1,0) [0|0] "" Vector__XXX
 SG_ TYPE_4 : 16|4@1+ (1,0) [0|0] "" Vector__XXX
 SG_ TYPE_5 : 20|4@1+ (1,0) [0|0] "" Vector__XXX
 SG_ TYPE_6 : 24|4@1+ (1,0) [0|0] "" Vector__XXX
 SG_ TYPE_7 : 28|4@1+ (1,0) [0|0] "" Vector__XXX
 SG_ TYPE_8 : 32|4@1+ (1,0) [0|0] "" Vector__XXX
 SG_ TYPE_9 : 36|4@1+ (1,0) [0|0] "" Vector__XXX
 SG_ TYPE_10 : 40|4@1+ (1,0) [0|0] "" Vector__XXX
 SG_ TYPE_11 : 44|4@1+ (1,0) [0|0] "" Vector__XXX
 SG_ TYPE_12 : 48|4@1+ (1,0) [0|0] "" Vector__XXX
 SG_ TYPE_13 : 52|4@1+ (1,0) [0|0] "" Vector__XXX
 SG_ TYPE_14 : 56|4@1+ (1,0) [0|0] "" Vector__XXX
 SG_ TYPE_15 : 60|4@1+ (1,0) [0|0] "" Vector__XXX

CM_ BO_ 2181379584 "Get types of parameters 128 to 143";
CM_ SG_ 2181379584 TYPE_0 "0: Unused, 1: Int, 2: Uint, 3: Float, 4: Boolean";
CM_ SG_ 2181379584 TYPE_1 "0: Unused, 1: Int, 2: Uint, 3: Float, 4: Boolean";
CM_ SG_ 2181379584 TYPE_2 "0: Unused, 1: Int, 2: Uint, 3: Float, 4: Boolean";
CM_ SG_ 2181379584 TYPE_3 "0: Unused, 1: Int, 2: Uint, 3: Float, 4: Boolean";
CM_ SG_ 2181379584 TYPE_4 "0: Unused, 1: Int, 2: Uint, 3: Float, 4: Boolean";
CM_ SG_ 2181379584 TYPE_5 "0: Unused, 1: Int, 2: Uint, 3: Float, 4: Boolean";
CM_ SG_ 2181379584 TYPE_6 "0: Unused, 1: Int, 2: Uint, 3: Float, 4: Boolean";
CM_ SG_ 2181379584 TYPE_7 "0: Unused, 1: Int, 2: Uint, 3: Float, 4: Boolean";
CM_ SG_ 2181379584 TYPE_8 "0: Unused, 1: Int, 2: Uint, 3: Float, 4: Boolean";
CM_ SG_ 2181379584 TYPE_9 "0: Unused, 1: Int, 2: Uint, 3: Float, 4: Boolean";
CM_ SG_ 2181379584 TYPE_10 "0: Unused, 1: Int, 2: Uint, 3: Float, 4: Boolean";
CM_ SG_ 2181379584 TYPE_11 "0: Unused, 1: Int, 2: Uint, 3: Float, 4: Boolean";
CM_ SG_ 2181379584 TYPE_12 "0: Unused, 1: Int, 2: Uint, 3: Float, 4: Boolean";
CM_ SG_ 2181379584 TYPE_13 "0: Unused, 1: Int, 2: Uint, 3: Float, 4: Boolean";
CM_ SG_ 2181379584 TYPE_14 "0: Unused, 1: Int, 2: Uint, 3: Float, 4: Boolean";
CM_ SG_ 2181379584 TYPE_15 "0: Unused, 1: Int, 2: Uint, 3: Float, 4: Boolean";

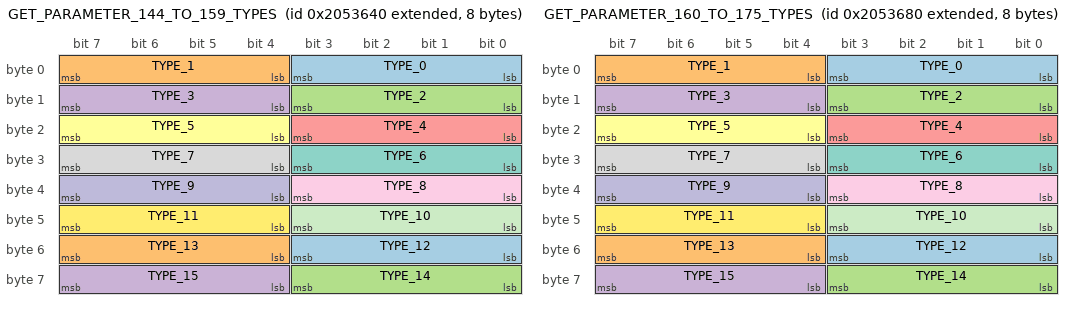
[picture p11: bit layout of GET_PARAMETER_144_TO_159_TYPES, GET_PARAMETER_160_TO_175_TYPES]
BO_ 2181379648 GET_PARAMETER_144_TO_159_TYPES: 8 Vector__XXX
 SG_ TYPE_0 : 0|4@1+ (1,0) [0|0] "" Vector__XXX
 SG_ TYPE_1 : 4|4@1+ (1,0) [0|0] "" Vector__XXX
 SG_ TYPE_2 : 8|4@1+ (1,0) [0|0] "" Vector__XXX
 SG_ TYPE_3 : 12|4@1+ (1,0) [0|0] "" Vector__XXX
 SG_ TYPE_4 : 16|4@1+ (1,0) [0|0] "" Vector__XXX
 SG_ TYPE_5 : 20|4@1+ (1,0) [0|0] "" Vector__XXX
 SG_ TYPE_6 : 24|4@1+ (1,0) [0|0] "" Vector__XXX
 SG_ TYPE_7 : 28|4@1+ (1,0) [0|0] "" Vector__XXX
 SG_ TYPE_8 : 32|4@1+ (1,0) [0|0] "" Vector__XXX
 SG_ TYPE_9 : 36|4@1+ (1,0) [0|0] "" Vector__XXX
 SG_ TYPE_10 : 40|4@1+ (1,0) [0|0] "" Vector__XXX
 SG_ TYPE_11 : 44|4@1+ (1,0) [0|0] "" Vector__XXX
 SG_ TYPE_12 : 48|4@1+ (1,0) [0|0] "" Vector__XXX
 SG_ TYPE_13 : 52|4@1+ (1,0) [0|0] "" Vector__XXX
 SG_ TYPE_14 : 56|4@1+ (1,0) [0|0] "" Vector__XXX
 SG_ TYPE_15 : 60|4@1+ (1,0) [0|0] "" Vector__XXX

CM_ BO_ 2181379648 "Get types of parameters 144 to 159";
CM_ SG_ 2181379648 TYPE_0 "0: Unused, 1: Int, 2: Uint, 3: Float, 4: Boolean";
CM_ SG_ 2181379648 TYPE_1 "0: Unused, 1: Int, 2: Uint, 3: Float, 4: Boolean";
CM_ SG_ 2181379648 TYPE_2 "0: Unused, 1: Int, 2: Uint, 3: Float, 4: Boolean";
CM_ SG_ 2181379648 TYPE_3 "0: Unused, 1: Int, 2: Uint, 3: Float, 4: Boolean";
CM_ SG_ 2181379648 TYPE_4 "0: Unused, 1: Int, 2: Uint, 3: Float, 4: Boolean";
CM_ SG_ 2181379648 TYPE_5 "0: Unused, 1: Int, 2: Uint, 3: Float, 4: Boolean";
CM_ SG_ 2181379648 TYPE_6 "0: Unused, 1: Int, 2: Uint, 3: Float, 4: Boolean";
CM_ SG_ 2181379648 TYPE_7 "0: Unused, 1: Int, 2: Uint, 3: Float, 4: Boolean";
CM_ SG_ 2181379648 TYPE_8 "0: Unused, 1: Int, 2: Uint, 3: Float, 4: Boolean";
CM_ SG_ 2181379648 TYPE_9 "0: Unused, 1: Int, 2: Uint, 3: Float, 4: Boolean";
CM_ SG_ 2181379648 TYPE_10 "0: Unused, 1: Int, 2: Uint, 3: Float, 4: Boolean";
CM_ SG_ 2181379648 TYPE_11 "0: Unused, 1: Int, 2: Uint, 3: Float, 4: Boolean";
CM_ SG_ 2181379648 TYPE_12 "0: Unused, 1: Int, 2: Uint, 3: Float, 4: Boolean";
CM_ SG_ 2181379648 TYPE_13 "0: Unused, 1: Int, 2: Uint, 3: Float, 4: Boolean";
CM_ SG_ 2181379648 TYPE_14 "0: Unused, 1: Int, 2: Uint, 3: Float, 4: Boolean";
CM_ SG_ 2181379648 TYPE_15 "0: Unused, 1: Int, 2: Uint, 3: Float, 4: Boolean";

BO_ 2181379712 GET_PARAMETER_160_TO_175_TYPES: 8 Vector__XXX
 SG_ TYPE_0 : 0|4@1+ (1,0) [0|0] "" Vector__XXX
 SG_ TYPE_1 : 4|4@1+ (1,0) [0|0] "" Vector__XXX
 SG_ TYPE_2 : 8|4@1+ (1,0) [0|0] "" Vector__XXX
 SG_ TYPE_3 : 12|4@1+ (1,0) [0|0] "" Vector__XXX
 SG_ TYPE_4 : 16|4@1+ (1,0) [0|0] "" Vector__XXX
 SG_ TYPE_5 : 20|4@1+ (1,0) [0|0] "" Vector__XXX
 SG_ TYPE_6 : 24|4@1+ (1,0) [0|0] "" Vector__XXX
 SG_ TYPE_7 : 28|4@1+ (1,0) [0|0] "" Vector__XXX
 SG_ TYPE_8 : 32|4@1+ (1,0) [0|0] "" Vector__XXX
 SG_ TYPE_9 : 36|4@1+ (1,0) [0|0] "" Vector__XXX
 SG_ TYPE_10 : 40|4@1+ (1,0) [0|0] "" Vector__XXX
 SG_ TYPE_11 : 44|4@1+ (1,0) [0|0] "" Vector__XXX
 SG_ TYPE_12 : 48|4@1+ (1,0) [0|0] "" Vector__XXX
 SG_ TYPE_13 : 52|4@1+ (1,0) [0|0] "" Vector__XXX
 SG_ TYPE_14 : 56|4@1+ (1,0) [0|0] "" Vector__XXX
 SG_ TYPE_15 : 60|4@1+ (1,0) [0|0] "" Vector__XXX

CM_ BO_ 2181379712 "Get types of parameters 160 to 175";
CM_ SG_ 2181379712 TYPE_0 "0: Unused, 1: Int, 2: Uint, 3: Float, 4: Boolean";
CM_ SG_ 2181379712 TYPE_1 "0: Unused, 1: Int, 2: Uint, 3: Float, 4: Boolean";
CM_ SG_ 2181379712 TYPE_2 "0: Unused, 1: Int, 2: Uint, 3: Float, 4: Boolean";
CM_ SG_ 2181379712 TYPE_3 "0: Unused, 1: Int, 2: Uint, 3: Float, 4: Boolean";
CM_ SG_ 2181379712 TYPE_4 "0: Unused, 1: Int, 2: Uint, 3: Float, 4: Boolean";
CM_ SG_ 2181379712 TYPE_5 "0: Unused, 1: Int, 2: Uint, 3: Float, 4: Boolean";
CM_ SG_ 2181379712 TYPE_6 "0: Unused, 1: Int, 2: Uint, 3: Float, 4: Boolean";
CM_ SG_ 2181379712 TYPE_7 "0: Unused, 1: Int, 2: Uint, 3: Float, 4: Boolean";
CM_ SG_ 2181379712 TYPE_8 "0: Unused, 1: Int, 2: Uint, 3: Float, 4: Boolean";
CM_ SG_ 2181379712 TYPE_9 "0: Unused, 1: Int, 2: Uint, 3: Float, 4: Boolean";
CM_ SG_ 2181379712 TYPE_10 "0: Unused, 1: Int, 2: Uint, 3: Float, 4: Boolean";
CM_ SG_ 2181379712 TYPE_11 "0: Unused, 1: Int, 2: Uint, 3: Float, 4: Boolean";
CM_ SG_ 2181379712 TYPE_12 "0: Unused, 1: Int, 2: Uint, 3: Float, 4: Boolean";
CM_ SG_ 2181379712 TYPE_13 "0: Unused, 1: Int, 2: Uint, 3: Float, 4: Boolean";
CM_ SG_ 2181379712 TYPE_14 "0: Unused, 1: Int, 2: Uint, 3: Float, 4: Boolean";
CM_ SG_ 2181379712 TYPE_15 "0: Unused, 1: Int, 2: Uint, 3: Float, 4: Boolean";

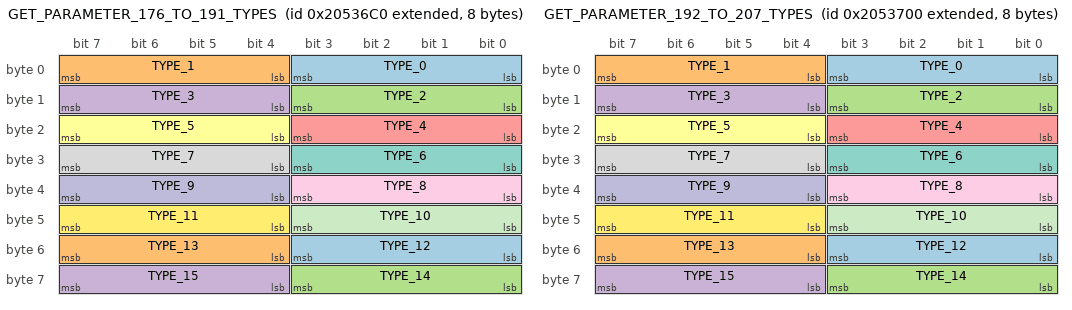
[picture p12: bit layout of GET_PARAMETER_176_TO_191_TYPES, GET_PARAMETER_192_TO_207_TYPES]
BO_ 2181379776 GET_PARAMETER_176_TO_191_TYPES: 8 Vector__XXX
 SG_ TYPE_0 : 0|4@1+ (1,0) [0|0] "" Vector__XXX
 SG_ TYPE_1 : 4|4@1+ (1,0) [0|0] "" Vector__XXX
 SG_ TYPE_2 : 8|4@1+ (1,0) [0|0] "" Vector__XXX
 SG_ TYPE_3 : 12|4@1+ (1,0) [0|0] "" Vector__XXX
 SG_ TYPE_4 : 16|4@1+ (1,0) [0|0] "" Vector__XXX
 SG_ TYPE_5 : 20|4@1+ (1,0) [0|0] "" Vector__XXX
 SG_ TYPE_6 : 24|4@1+ (1,0) [0|0] "" Vector__XXX
 SG_ TYPE_7 : 28|4@1+ (1,0) [0|0] "" Vector__XXX
 SG_ TYPE_8 : 32|4@1+ (1,0) [0|0] "" Vector__XXX
 SG_ TYPE_9 : 36|4@1+ (1,0) [0|0] "" Vector__XXX
 SG_ TYPE_10 : 40|4@1+ (1,0) [0|0] "" Vector__XXX
 SG_ TYPE_11 : 44|4@1+ (1,0) [0|0] "" Vector__XXX
 SG_ TYPE_12 : 48|4@1+ (1,0) [0|0] "" Vector__XXX
 SG_ TYPE_13 : 52|4@1+ (1,0) [0|0] "" Vector__XXX
 SG_ TYPE_14 : 56|4@1+ (1,0) [0|0] "" Vector__XXX
 SG_ TYPE_15 : 60|4@1+ (1,0) [0|0] "" Vector__XXX

CM_ BO_ 2181379776 "Get types of parameters 176 to 191";
CM_ SG_ 2181379776 TYPE_0 "0: Unused, 1: Int, 2: Uint, 3: Float, 4: Boolean";
CM_ SG_ 2181379776 TYPE_1 "0: Unused, 1: Int, 2: Uint, 3: Float, 4: Boolean";
CM_ SG_ 2181379776 TYPE_2 "0: Unused, 1: Int, 2: Uint, 3: Float, 4: Boolean";
CM_ SG_ 2181379776 TYPE_3 "0: Unused, 1: Int, 2: Uint, 3: Float, 4: Boolean";
CM_ SG_ 2181379776 TYPE_4 "0: Unused, 1: Int, 2: Uint, 3: Float, 4: Boolean";
CM_ SG_ 2181379776 TYPE_5 "0: Unused, 1: Int, 2: Uint, 3: Float, 4: Boolean";
CM_ SG_ 2181379776 TYPE_6 "0: Unused, 1: Int, 2: Uint, 3: Float, 4: Boolean";
CM_ SG_ 2181379776 TYPE_7 "0: Unused, 1: Int, 2: Uint, 3: Float, 4: Boolean";
CM_ SG_ 2181379776 TYPE_8 "0: Unused, 1: Int, 2: Uint, 3: Float, 4: Boolean";
CM_ SG_ 2181379776 TYPE_9 "0: Unused, 1: Int, 2: Uint, 3: Float, 4: Boolean";
CM_ SG_ 2181379776 TYPE_10 "0: Unused, 1: Int, 2: Uint, 3: Float, 4: Boolean";
CM_ SG_ 2181379776 TYPE_11 "0: Unused, 1: Int, 2: Uint, 3: Float, 4: Boolean";
CM_ SG_ 2181379776 TYPE_12 "0: Unused, 1: Int, 2: Uint, 3: Float, 4: Boolean";
CM_ SG_ 2181379776 TYPE_13 "0: Unused, 1: Int, 2: Uint, 3: Float, 4: Boolean";
CM_ SG_ 2181379776 TYPE_14 "0: Unused, 1: Int, 2: Uint, 3: Float, 4: Boolean";
CM_ SG_ 2181379776 TYPE_15 "0: Unused, 1: Int, 2: Uint, 3: Float, 4: Boolean";

BO_ 2181379840 GET_PARAMETER_192_TO_207_TYPES: 8 Vector__XXX
 SG_ TYPE_0 : 0|4@1+ (1,0) [0|0] "" Vector__XXX
 SG_ TYPE_1 : 4|4@1+ (1,0) [0|0] "" Vector__XXX
 SG_ TYPE_2 : 8|4@1+ (1,0) [0|0] "" Vector__XXX
 SG_ TYPE_3 : 12|4@1+ (1,0) [0|0] "" Vector__XXX
 SG_ TYPE_4 : 16|4@1+ (1,0) [0|0] "" Vector__XXX
 SG_ TYPE_5 : 20|4@1+ (1,0) [0|0] "" Vector__XXX
 SG_ TYPE_6 : 24|4@1+ (1,0) [0|0] "" Vector__XXX
 SG_ TYPE_7 : 28|4@1+ (1,0) [0|0] "" Vector__XXX
 SG_ TYPE_8 : 32|4@1+ (1,0) [0|0] "" Vector__XXX
 SG_ TYPE_9 : 36|4@1+ (1,0) [0|0] "" Vector__XXX
 SG_ TYPE_10 : 40|4@1+ (1,0) [0|0] "" Vector__XXX
 SG_ TYPE_11 : 44|4@1+ (1,0) [0|0] "" Vector__XXX
 SG_ TYPE_12 : 48|4@1+ (1,0) [0|0] "" Vector__XXX
 SG_ TYPE_13 : 52|4@1+ (1,0) [0|0] "" Vector__XXX
 SG_ TYPE_14 : 56|4@1+ (1,0) [0|0] "" Vector__XXX
 SG_ TYPE_15 : 60|4@1+ (1,0) [0|0] "" Vector__XXX

CM_ BO_ 2181379840 "Get types of parameters 192 to 207";
CM_ SG_ 2181379840 TYPE_0 "0: Unused, 1: Int, 2: Uint, 3: Float, 4: Boolean";
CM_ SG_ 2181379840 TYPE_1 "0: Unused, 1: Int, 2: Uint, 3: Float, 4: Boolean";
CM_ SG_ 2181379840 TYPE_2 "0: Unused, 1: Int, 2: Uint, 3: Float, 4: Boolean";
CM_ SG_ 2181379840 TYPE_3 "0: Unused, 1: Int, 2: Uint, 3: Float, 4: Boolean";
CM_ SG_ 2181379840 TYPE_4 "0: Unused, 1: Int, 2: Uint, 3: Float, 4: Boolean";
CM_ SG_ 2181379840 TYPE_5 "0: Unused, 1: Int, 2: Uint, 3: Float, 4: Boolean";
CM_ SG_ 2181379840 TYPE_6 "0: Unused, 1: Int, 2: Uint, 3: Float, 4: Boolean";
CM_ SG_ 2181379840 TYPE_7 "0: Unused, 1: Int, 2: Uint, 3: Float, 4: Boolean";
CM_ SG_ 2181379840 TYPE_8 "0: Unused, 1: Int, 2: Uint, 3: Float, 4: Boolean";
CM_ SG_ 2181379840 TYPE_9 "0: Unused, 1: Int, 2: Uint, 3: Float, 4: Boolean";
CM_ SG_ 2181379840 TYPE_10 "0: Unused, 1: Int, 2: Uint, 3: Float, 4: Boolean";
CM_ SG_ 2181379840 TYPE_11 "0: Unused, 1: Int, 2: Uint, 3: Float, 4: Boolean";
CM_ SG_ 2181379840 TYPE_12 "0: Unused, 1: Int, 2: Uint, 3: Float, 4: Boolean";
CM_ SG_ 2181379840 TYPE_13 "0: Unused, 1: Int, 2: Uint, 3: Float, 4: Boolean";
CM_ SG_ 2181379840 TYPE_14 "0: Unused, 1: Int, 2: Uint, 3: Float, 4: Boolean";
CM_ SG_ 2181379840 TYPE_15 "0: Unused, 1: Int, 2: Uint, 3: Float, 4: Boolean";

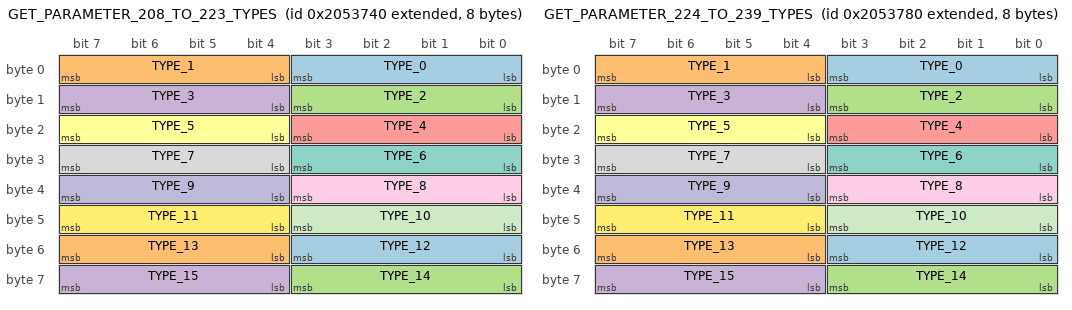
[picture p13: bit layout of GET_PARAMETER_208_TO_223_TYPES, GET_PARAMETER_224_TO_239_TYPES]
BO_ 2181379904 GET_PARAMETER_208_TO_223_TYPES: 8 Vector__XXX
 SG_ TYPE_0 : 0|4@1+ (1,0) [0|0] "" Vector__XXX
 SG_ TYPE_1 : 4|4@1+ (1,0) [0|0] "" Vector__XXX
 SG_ TYPE_2 : 8|4@1+ (1,0) [0|0] "" Vector__XXX
 SG_ TYPE_3 : 12|4@1+ (1,0) [0|0] "" Vector__XXX
 SG_ TYPE_4 : 16|4@1+ (1,0) [0|0] "" Vector__XXX
 SG_ TYPE_5 : 20|4@1+ (1,0) [0|0] "" Vector__XXX
 SG_ TYPE_6 : 24|4@1+ (1,0) [0|0] "" Vector__XXX
 SG_ TYPE_7 : 28|4@1+ (1,0) [0|0] "" Vector__XXX
 SG_ TYPE_8 : 32|4@1+ (1,0) [0|0] "" Vector__XXX
 SG_ TYPE_9 : 36|4@1+ (1,0) [0|0] "" Vector__XXX
 SG_ TYPE_10 : 40|4@1+ (1,0) [0|0] "" Vector__XXX
 SG_ TYPE_11 : 44|4@1+ (1,0) [0|0] "" Vector__XXX
 SG_ TYPE_12 : 48|4@1+ (1,0) [0|0] "" Vector__XXX
 SG_ TYPE_13 : 52|4@1+ (1,0) [0|0] "" Vector__XXX
 SG_ TYPE_14 : 56|4@1+ (1,0) [0|0] "" Vector__XXX
 SG_ TYPE_15 : 60|4@1+ (1,0) [0|0] "" Vector__XXX

CM_ BO_ 2181379904 "Get types of parameters 208 to 223";
CM_ SG_ 2181379904 TYPE_0 "0: Unused, 1: Int, 2: Uint, 3: Float, 4: Boolean";
CM_ SG_ 2181379904 TYPE_1 "0: Unused, 1: Int, 2: Uint, 3: Float, 4: Boolean";
CM_ SG_ 2181379904 TYPE_2 "0: Unused, 1: Int, 2: Uint, 3: Float, 4: Boolean";
CM_ SG_ 2181379904 TYPE_3 "0: Unused, 1: Int, 2: Uint, 3: Float, 4: Boolean";
CM_ SG_ 2181379904 TYPE_4 "0: Unused, 1: Int, 2: Uint, 3: Float, 4: Boolean";
CM_ SG_ 2181379904 TYPE_5 "0: Unused, 1: Int, 2: Uint, 3: Float, 4: Boolean";
CM_ SG_ 2181379904 TYPE_6 "0: Unused, 1: Int, 2: Uint, 3: Float, 4: Boolean";
CM_ SG_ 2181379904 TYPE_7 "0: Unused, 1: Int, 2: Uint, 3: Float, 4: Boolean";
CM_ SG_ 2181379904 TYPE_8 "0: Unused, 1: Int, 2: Uint, 3: Float, 4: Boolean";
CM_ SG_ 2181379904 TYPE_9 "0: Unused, 1: Int, 2: Uint, 3: Float, 4: Boolean";
CM_ SG_ 2181379904 TYPE_10 "0: Unused, 1: Int, 2: Uint, 3: Float, 4: Boolean";
CM_ SG_ 2181379904 TYPE_11 "0: Unused, 1: Int, 2: Uint, 3: Float, 4: Boolean";
CM_ SG_ 2181379904 TYPE_12 "0: Unused, 1: Int, 2: Uint, 3: Float, 4: Boolean";
CM_ SG_ 2181379904 TYPE_13 "0: Unused, 1: Int, 2: Uint, 3: Float, 4: Boolean";
CM_ SG_ 2181379904 TYPE_14 "0: Unused, 1: Int, 2: Uint, 3: Float, 4: Boolean";
CM_ SG_ 2181379904 TYPE_15 "0: Unused, 1: Int, 2: Uint, 3: Float, 4: Boolean";

BO_ 2181379968 GET_PARAMETER_224_TO_239_TYPES: 8 Vector__XXX
 SG_ TYPE_0 : 0|4@1+ (1,0) [0|0] "" Vector__XXX
 SG_ TYPE_1 : 4|4@1+ (1,0) [0|0] "" Vector__XXX
 SG_ TYPE_2 : 8|4@1+ (1,0) [0|0] "" Vector__XXX
 SG_ TYPE_3 : 12|4@1+ (1,0) [0|0] "" Vector__XXX
 SG_ TYPE_4 : 16|4@1+ (1,0) [0|0] "" Vector__XXX
 SG_ TYPE_5 : 20|4@1+ (1,0) [0|0] "" Vector__XXX
 SG_ TYPE_6 : 24|4@1+ (1,0) [0|0] "" Vector__XXX
 SG_ TYPE_7 : 28|4@1+ (1,0) [0|0] "" Vector__XXX
 SG_ TYPE_8 : 32|4@1+ (1,0) [0|0] "" Vector__XXX
 SG_ TYPE_9 : 36|4@1+ (1,0) [0|0] "" Vector__XXX
 SG_ TYPE_10 : 40|4@1+ (1,0) [0|0] "" Vector__XXX
 SG_ TYPE_11 : 44|4@1+ (1,0) [0|0] "" Vector__XXX
 SG_ TYPE_12 : 48|4@1+ (1,0) [0|0] "" Vector__XXX
 SG_ TYPE_13 : 52|4@1+ (1,0) [0|0] "" Vector__XXX
 SG_ TYPE_14 : 56|4@1+ (1,0) [0|0] "" Vector__XXX
 SG_ TYPE_15 : 60|4@1+ (1,0) [0|0] "" Vector__XXX

CM_ BO_ 2181379968 "Get types of parameters 224 to 239";
CM_ SG_ 2181379968 TYPE_0 "0: Unused, 1: Int, 2: Uint, 3: Float, 4: Boolean";
CM_ SG_ 2181379968 TYPE_1 "0: Unused, 1: Int, 2: Uint, 3: Float, 4: Boolean";
CM_ SG_ 2181379968 TYPE_2 "0: Unused, 1: Int, 2: Uint, 3: Float, 4: Boolean";
CM_ SG_ 2181379968 TYPE_3 "0: Unused, 1: Int, 2: Uint, 3: Float, 4: Boolean";
CM_ SG_ 2181379968 TYPE_4 "0: Unused, 1: Int, 2: Uint, 3: Float, 4: Boolean";
CM_ SG_ 2181379968 TYPE_5 "0: Unused, 1: Int, 2: Uint, 3: Float, 4: Boolean";
CM_ SG_ 2181379968 TYPE_6 "0: Unused, 1: Int, 2: Uint, 3: Float, 4: Boolean";
CM_ SG_ 2181379968 TYPE_7 "0: Unused, 1: Int, 2: Uint, 3: Float, 4: Boolean";
CM_ SG_ 2181379968 TYPE_8 "0: Unused, 1: Int, 2: Uint, 3: Float, 4: Boolean";
CM_ SG_ 2181379968 TYPE_9 "0: Unused, 1: Int, 2: Uint, 3: Float, 4: Boolean";
CM_ SG_ 2181379968 TYPE_10 "0: Unused, 1: Int, 2: Uint, 3: Float, 4: Boolean";
CM_ SG_ 2181379968 TYPE_11 "0: Unused, 1: Int, 2: Uint, 3: Float, 4: Boolean";
CM_ SG_ 2181379968 TYPE_12 "0: Unused, 1: Int, 2: Uint, 3: Float, 4: Boolean";
CM_ SG_ 2181379968 TYPE_13 "0: Unused, 1: Int, 2: Uint, 3: Float, 4: Boolean";
CM_ SG_ 2181379968 TYPE_14 "0: Unused, 1: Int, 2: Uint, 3: Float, 4: Boolean";
CM_ SG_ 2181379968 TYPE_15 "0: Unused, 1: Int, 2: Uint, 3: Float, 4: Boolean";

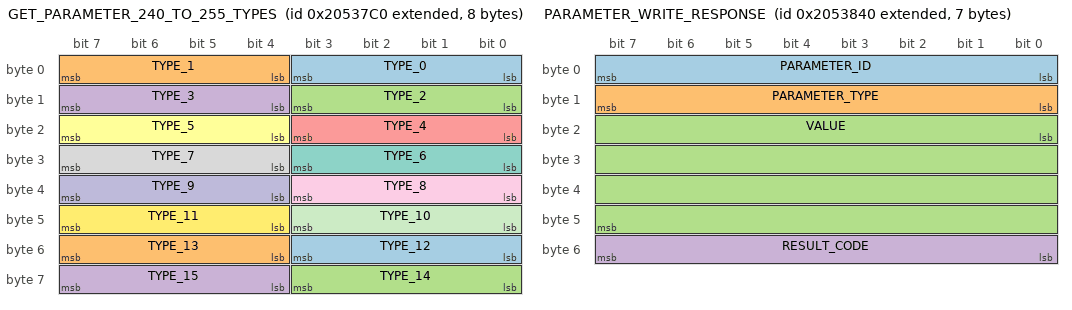
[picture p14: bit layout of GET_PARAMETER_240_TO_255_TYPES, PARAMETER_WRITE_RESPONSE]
BO_ 2181380032 GET_PARAMETER_240_TO_255_TYPES: 8 Vector__XXX
 SG_ TYPE_0 : 0|4@1+ (1,0) [0|0] "" Vector__XXX
 SG_ TYPE_1 : 4|4@1+ (1,0) [0|0] "" Vector__XXX
 SG_ TYPE_2 : 8|4@1+ (1,0) [0|0] "" Vector__XXX
 SG_ TYPE_3 : 12|4@1+ (1,0) [0|0] "" Vector__XXX
 SG_ TYPE_4 : 16|4@1+ (1,0) [0|0] "" Vector__XXX
 SG_ TYPE_5 : 20|4@1+ (1,0) [0|0] "" Vector__XXX
 SG_ TYPE_6 : 24|4@1+ (1,0) [0|0] "" Vector__XXX
 SG_ TYPE_7 : 28|4@1+ (1,0) [0|0] "" Vector__XXX
 SG_ TYPE_8 : 32|4@1+ (1,0) [0|0] "" Vector__XXX
 SG_ TYPE_9 : 36|4@1+ (1,0) [0|0] "" Vector__XXX
 SG_ TYPE_10 : 40|4@1+ (1,0) [0|0] "" Vector__XXX
 SG_ TYPE_11 : 44|4@1+ (1,0) [0|0] "" Vector__XXX
 SG_ TYPE_12 : 48|4@1+ (1,0) [0|0] "" Vector__XXX
 SG_ TYPE_13 : 52|4@1+ (1,0) [0|0] "" Vector__XXX
 SG_ TYPE_14 : 56|4@1+ (1,0) [0|0] "" Vector__XXX
 SG_ TYPE_15 : 60|4@1+ (1,0) [0|0] "" Vector__XXX

CM_ BO_ 2181380032 "Get types of parameters 240 to 255";
CM_ SG_ 2181380032 TYPE_0 "0: Unused, 1: Int, 2: Uint, 3: Float, 4: Boolean";
CM_ SG_ 2181380032 TYPE_1 "0: Unused, 1: Int, 2: Uint, 3: Float, 4: Boolean";
CM_ SG_ 2181380032 TYPE_2 "0: Unused, 1: Int, 2: Uint, 3: Float, 4: Boolean";
CM_ SG_ 2181380032 TYPE_3 "0: Unused, 1: Int, 2: Uint, 3: Float, 4: Boolean";
CM_ SG_ 2181380032 TYPE_4 "0: Unused, 1: Int, 2: Uint, 3: Float, 4: Boolean";
CM_ SG_ 2181380032 TYPE_5 "0: Unused, 1: Int, 2: Uint, 3: Float, 4: Boolean";
CM_ SG_ 2181380032 TYPE_6 "0: Unused, 1: Int, 2: Uint, 3: Float, 4: Boolean";
CM_ SG_ 2181380032 TYPE_7 "0: Unused, 1: Int, 2: Uint, 3: Float, 4: Boolean";
CM_ SG_ 2181380032 TYPE_8 "0: Unused, 1: Int, 2: Uint, 3: Float, 4: Boolean";
CM_ SG_ 2181380032 TYPE_9 "0: Unused, 1: Int, 2: Uint, 3: Float, 4: Boolean";
CM_ SG_ 2181380032 TYPE_10 "0: Unused, 1: Int, 2: Uint, 3: Float, 4: Boolean";
CM_ SG_ 2181380032 TYPE_11 "0: Unused, 1: Int, 2: Uint, 3: Float, 4: Boolean";
CM_ SG_ 2181380032 TYPE_12 "0: Unused, 1: Int, 2: Uint, 3: Float, 4: Boolean";
CM_ SG_ 2181380032 TYPE_13 "0: Unused, 1: Int, 2: Uint, 3: Float, 4: Boolean";
CM_ SG_ 2181380032 TYPE_14 "0: Unused, 1: Int, 2: Uint, 3: Float, 4: Boolean";
CM_ SG_ 2181380032 TYPE_15 "0: Unused, 1: Int, 2: Uint, 3: Float, 4: Boolean";

BO_ 2181380096 PARAMETER_WRITE: 5 Vector__XXX
 SG_ PARAMETER_ID : 0|8@1+ (1,0) [0|0] "" Vector__XXX
 SG_ VALUE : 8|32@1+ (1,0) [0|0] "" Vector__XXX

CM_ BO_ 2181380096 "Write a single parameter value. In response, a Parameter Write Response frame will be sent.";
CM_ SG_ 2181380096 VALUE "The actual type of this data depends on the Parameter Type of the parameter in question";

BO_ 2181380160 PARAMETER_WRITE_RESPONSE: 7 Vector__XXX
 SG_ PARAMETER_ID : 0|8@1+ (1,0) [0|0] "" Vector__XXX
 SG_ PARAMETER_TYPE : 8|8@1+ (1,0) [0|0] "" Vector__XXX
 SG_ VALUE : 16|32@1+ (1,0) [0|0] "" Vector__XXX
 SG_ RESULT_CODE : 48|8@1+ (1,0) [0|0] "" Vector__XXX

CM_ BO_ 2181380160 "Response for a parameter write (including a write done as part of a dual-write)";
CM_ SG_ 2181380160 PARAMETER_TYPE "0: Unused, 1: Int, 2: Uint, 3: Float, 4: Boolean";
CM_ SG_ 2181380160 VALUE "The actual type of this field is specified by the Parameter Type field. Contains the current value of the parameter, which will not match what was specified in the write command if the write failed.";
CM_ SG_ 2181380160 RESULT_CODE "0: Success, 1: Invalid ID, 2: Mismatched Type, 3: Access Mode, 4: Invalid, 5: Not Implemented";

BO_ 2181381120 READ_PARAMETER_0_AND_1: 8 Vector__XXX
 SG_ FIRST_PARAMETER_VALUE : 0|32@1+ (1,0) [0|0] "" Vector__XXX
 SG_ SECOND_PARAMETER_VALUE : 32|32@1+ (1,0) [0|0] "" Vector__XXX

CM_ BO_ 2181381120 "Read parameter 0 and 1 at the same time. SPARK MAX does not currently support this in v25.0.0-prerelease.4";
CM_ SG_ 2181381120 FIRST_PARAMETER_VALUE "The actual type of this data depends on the Parameter Type of the parameter in question";
CM_ SG_ 2181381120 SECOND_PARAMETER_VALUE "The actual type of this data depends on the Parameter Type of the parameter in question";

BO_ 2181381184 READ_PARAMETER_2_AND_3: 8 Vector__XXX
 SG_ FIRST_PARAMETER_VALUE : 0|32@1+ (1,0) [0|0] "" Vector__XXX
 SG_ SECOND_PARAMETER_VALUE : 32|32@1+ (1,0) [0|0] "" Vector__XXX

CM_ BO_ 2181381184 "Read parameter 2 and 3 at the same time. SPARK MAX does not currently support this in v25.0.0-prerelease.4";
CM_ SG_ 2181381184 FIRST_PARAMETER_VALUE "The actual type of this data depends on the Parameter Type of the parameter in question";
CM_ SG_ 2181381184 SECOND_PARAMETER_VALUE "The actual type of this data depends on the Parameter Type of the parameter in question";

BO_ 2181381248 READ_PARAMETER_4_AND_5: 8 Vector__XXX
 SG_ FIRST_PARAMETER_VALUE : 0|32@1+ (1,0) [0|0] "" Vector__XXX
 SG_ SECOND_PARAMETER_VALUE : 32|32@1+ (1,0) [0|0] "" Vector__XXX

CM_ BO_ 2181381248 "Read parameter 4 and 5 at the same time. SPARK MAX does not currently support this in v25.0.0-prerelease.4";
CM_ SG_ 2181381248 FIRST_PARAMETER_VALUE "The actual type of this data depends on the Parameter Type of the parameter in question";
CM_ SG_ 2181381248 SECOND_PARAMETER_VALUE "The actual type of this data depends on the Parameter Type of the parameter in question";

BO_ 2181381312 READ_PARAMETER_6_AND_7: 8 Vector__XXX
 SG_ FIRST_PARAMETER_VALUE : 0|32@1+ (1,0) [0|0] "" Vector__XXX
 SG_ SECOND_PARAMETER_VALUE : 32|32@1+ (1,0) [0|0] "" Vector__XXX

CM_ BO_ 2181381312 "Read parameter 6 and 7 at the same time. SPARK MAX does not currently support this in v25.0.0-prerelease.4";
CM_ SG_ 2181381312 FIRST_PARAMETER_VALUE "The actual type of this data depends on the Parameter Type of the parameter in question";
CM_ SG_ 2181381312 SECOND_PARAMETER_VALUE "The actual type of this data depends on the Parameter Type of the parameter in question";

BO_ 2181381376 READ_PARAMETER_8_AND_9: 8 Vector__XXX
 SG_ FIRST_PARAMETER_VALUE : 0|32@1+ (1,0) [0|0] "" Vector__XXX
 SG_ SECOND_PARAMETER_VALUE : 32|32@1+ (1,0) [0|0] "" Vector__XXX

CM_ BO_ 2181381376 "Read parameter 8 and 9 at the same time. SPARK MAX does not currently support this in v25.0.0-prerelease.4";
CM_ SG_ 2181381376 FIRST_PARAMETER_VALUE "The actual type of this data depends on the Parameter Type of the parameter in question";
CM_ SG_ 2181381376 SECOND_PARAMETER_VALUE "The actual type of this data depends on the Parameter Type of the parameter in question";

BO_ 2181381440 READ_PARAMETER_10_AND_11: 8 Vector__XXX
 SG_ FIRST_PARAMETER_VALUE : 0|32@1+ (1,0) [0|0] "" Vector__XXX
 SG_ SECOND_PARAMETER_VALUE : 32|32@1+ (1,0) [0|0] "" Vector__XXX

CM_ BO_ 2181381440 "Read parameter 10 and 11 at the same time. SPARK MAX does not currently support this in v25.0.0-prerelease.4";
CM_ SG_ 2181381440 FIRST_PARAMETER_VALUE "The actual type of this data depends on the Parameter Type of the parameter in question";
CM_ SG_ 2181381440 SECOND_PARAMETER_VALUE "The actual type of this data depends on the Parameter Type of the parameter in question";

BO_ 2181381504 READ_PARAMETER_12_AND_13: 8 Vector__XXX
 SG_ FIRST_PARAMETER_VALUE : 0|32@1+ (1,0) [0|0] "" Vector__XXX
 SG_ SECOND_PARAMETER_VALUE : 32|32@1+ (1,0) [0|0] "" Vector__XXX

CM_ BO_ 2181381504 "Read parameter 12 and 13 at the same time. SPARK MAX does not currently support this in v25.0.0-prerelease.4";
CM_ SG_ 2181381504 FIRST_PARAMETER_VALUE "The actual type of this data depends on the Parameter Type of the parameter in question";
CM_ SG_ 2181381504 SECOND_PARAMETER_VALUE "The actual type of this data depends on the Parameter Type of the parameter in question";

BO_ 2181381568 READ_PARAMETER_14_AND_15: 8 Vector__XXX
 SG_ FIRST_PARAMETER_VALUE : 0|32@1+ (1,0) [0|0] "" Vector__XXX
 SG_ SECOND_PARAMETER_VALUE : 32|32@1+ (1,0) [0|0] "" Vector__XXX

CM_ BO_ 2181381568 "Read parameter 14 and 15 at the same time. SPARK MAX does not currently support this in v25.0.0-prerelease.4";
CM_ SG_ 2181381568 FIRST_PARAMETER_VALUE "The actual type of this data depends on the Parameter Type of the parameter in question";
CM_ SG_ 2181381568 SECOND_PARAMETER_VALUE "The actual type of this data depends on the Parameter Type of the parameter in question";

BO_ 2181381632 READ_PARAMETER_16_AND_17: 8 Vector__XXX
 SG_ FIRST_PARAMETER_VALUE : 0|32@1+ (1,0) [0|0] "" Vector__XXX
 SG_ SECOND_PARAMETER_VALUE : 32|32@1+ (1,0) [0|0] "" Vector__XXX

CM_ BO_ 2181381632 "Read parameter 16 and 17 at the same time. SPARK MAX does not currently support this in v25.0.0-prerelease.4";
CM_ SG_ 2181381632 FIRST_PARAMETER_VALUE "The actual type of this data depends on the Parameter Type of the parameter in question";
CM_ SG_ 2181381632 SECOND_PARAMETER_VALUE "The actual type of this data depends on the Parameter Type of the parameter in question";

BO_ 2181381696 READ_PARAMETER_18_AND_19: 8 Vector__XXX
 SG_ FIRST_PARAMETER_VALUE : 0|32@1+ (1,0) [0|0] "" Vector__XXX
 SG_ SECOND_PARAMETER_VALUE : 32|32@1+ (1,0) [0|0] "" Vector__XXX

CM_ BO_ 2181381696 "Read parameter 18 and 19 at the same time. SPARK MAX does not currently support this in v25.0.0-prerelease.4";
CM_ SG_ 2181381696 FIRST_PARAMETER_VALUE "The actual type of this data depends on the Parameter Type of the parameter in question";
CM_ SG_ 2181381696 SECOND_PARAMETER_VALUE "The actual type of this data depends on the Parameter Type of the parameter in question";

BO_ 2181381760 READ_PARAMETER_20_AND_21: 8 Vector__XXX
 SG_ FIRST_PARAMETER_VALUE : 0|32@1+ (1,0) [0|0] "" Vector__XXX
 SG_ SECOND_PARAMETER_VALUE : 32|32@1+ (1,0) [0|0] "" Vector__XXX

CM_ BO_ 2181381760 "Read parameter 20 and 21 at the same time. SPARK MAX does not currently support this in v25.0.0-prerelease.4";
CM_ SG_ 2181381760 FIRST_PARAMETER_VALUE "The actual type of this data depends on the Parameter Type of the parameter in question";
CM_ SG_ 2181381760 SECOND_PARAMETER_VALUE "The actual type of this data depends on the Parameter Type of the parameter in question";

BO_ 2181381824 READ_PARAMETER_22_AND_23: 8 Vector__XXX
 SG_ FIRST_PARAMETER_VALUE : 0|32@1+ (1,0) [0|0] "" Vector__XXX
 SG_ SECOND_PARAMETER_VALUE : 32|32@1+ (1,0) [0|0] "" Vector__XXX

CM_ BO_ 2181381824 "Read parameter 22 and 23 at the same time. SPARK MAX does not currently support this in v25.0.0-prerelease.4";
CM_ SG_ 2181381824 FIRST_PARAMETER_VALUE "The actual type of this data depends on the Parameter Type of the parameter in question";
CM_ SG_ 2181381824 SECOND_PARAMETER_VALUE "The actual type of this data depends on the Parameter Type of the parameter in question";

BO_ 2181381888 READ_PARAMETER_24_AND_25: 8 Vector__XXX
 SG_ FIRST_PARAMETER_VALUE : 0|32@1+ (1,0) [0|0] "" Vector__XXX
 SG_ SECOND_PARAMETER_VALUE : 32|32@1+ (1,0) [0|0] "" Vector__XXX

CM_ BO_ 2181381888 "Read parameter 24 and 25 at the same time. SPARK MAX does not currently support this in v25.0.0-prerelease.4";
CM_ SG_ 2181381888 FIRST_PARAMETER_VALUE "The actual type of this data depends on the Parameter Type of the parameter in question";
CM_ SG_ 2181381888 SECOND_PARAMETER_VALUE "The actual type of this data depends on the Parameter Type of the parameter in question";

BO_ 2181381952 READ_PARAMETER_26_AND_27: 8 Vector__XXX
 SG_ FIRST_PARAMETER_VALUE : 0|32@1+ (1,0) [0|0] "" Vector__XXX
 SG_ SECOND_PARAMETER_VALUE : 32|32@1+ (1,0) [0|0] "" Vector__XXX

CM_ BO_ 2181381952 "Read parameter 26 and 27 at the same time. SPARK MAX does not currently support this in v25.0.0-prerelease.4";
CM_ SG_ 2181381952 FIRST_PARAMETER_VALUE "The actual type of this data depends on the Parameter Type of the parameter in question";
CM_ SG_ 2181381952 SECOND_PARAMETER_VALUE "The actual type of this data depends on the Parameter Type of the parameter in question";

BO_ 2181382016 READ_PARAMETER_28_AND_29: 8 Vector__XXX
 SG_ FIRST_PARAMETER_VALUE : 0|32@1+ (1,0) [0|0] "" Vector__XXX
 SG_ SECOND_PARAMETER_VALUE : 32|32@1+ (1,0) [0|0] "" Vector__XXX

CM_ BO_ 2181382016 "Read parameter 28 and 29 at the same time. SPARK MAX does not currently support this in v25.0.0-prerelease.4";
CM_ SG_ 2181382016 FIRST_PARAMETER_VALUE "The actual type of this data depends on the Parameter Type of the parameter in question";
CM_ SG_ 2181382016 SECOND_PARAMETER_VALUE "The actual type of this data depends on the Parameter Type of the parameter in question";

BO_ 2181382080 READ_PARAMETER_30_AND_31: 8 Vector__XXX
 SG_ FIRST_PARAMETER_VALUE : 0|32@1+ (1,0) [0|0] "" Vector__XXX
 SG_ SECOND_PARAMETER_VALUE : 32|32@1+ (1,0) [0|0] "" Vector__XXX

CM_ BO_ 2181382080 "Read parameter 30 and 31 at the same time. SPARK MAX does not currently support this in v25.0.0-prerelease.4";
CM_ SG_ 2181382080 FIRST_PARAMETER_VALUE "The actual type of this data depends on the Parameter Type of the parameter in question";
CM_ SG_ 2181382080 SECOND_PARAMETER_VALUE "The actual type of this data depends on the Parameter Type of the parameter in question";

BO_ 2181382144 READ_PARAMETER_32_AND_33: 8 Vector__XXX
 SG_ FIRST_PARAMETER_VALUE : 0|32@1+ (1,0) [0|0] "" Vector__XXX
 SG_ SECOND_PARAMETER_VALUE : 32|32@1+ (1,0) [0|0] "" Vector__XXX

CM_ BO_ 2181382144 "Read parameter 32 and 33 at the same time. SPARK MAX does not currently support this in v25.0.0-prerelease.4";
CM_ SG_ 2181382144 FIRST_PARAMETER_VALUE "The actual type of this data depends on the Parameter Type of the parameter in question";
CM_ SG_ 2181382144 SECOND_PARAMETER_VALUE "The actual type of this data depends on the Parameter Type of the parameter in question";

BO_ 2181382208 READ_PARAMETER_34_AND_35: 8 Vector__XXX
 SG_ FIRST_PARAMETER_VALUE : 0|32@1+ (1,0) [0|0] "" Vector__XXX
 SG_ SECOND_PARAMETER_VALUE : 32|32@1+ (1,0) [0|0] "" Vector__XXX

CM_ BO_ 2181382208 "Read parameter 34 and 35 at the same time. SPARK MAX does not currently support this in v25.0.0-prerelease.4";
CM_ SG_ 2181382208 FIRST_PARAMETER_VALUE "The actual type of this data depends on the Parameter Type of the parameter in question";
CM_ SG_ 2181382208 SECOND_PARAMETER_VALUE "The actual type of this data depends on the Parameter Type of the parameter in question";

BO_ 2181382272 READ_PARAMETER_36_AND_37: 8 Vector__XXX
 SG_ FIRST_PARAMETER_VALUE : 0|32@1+ (1,0) [0|0] "" Vector__XXX
 SG_ SECOND_PARAMETER_VALUE : 32|32@1+ (1,0) [0|0] "" Vector__XXX

CM_ BO_ 2181382272 "Read parameter 36 and 37 at the same time. SPARK MAX does not currently support this in v25.0.0-prerelease.4";
CM_ SG_ 2181382272 FIRST_PARAMETER_VALUE "The actual type of this data depends on the Parameter Type of the parameter in question";
CM_ SG_ 2181382272 SECOND_PARAMETER_VALUE "The actual type of this data depends on the Parameter Type of the parameter in question";

BO_ 2181382336 READ_PARAMETER_38_AND_39: 8 Vector__XXX
 SG_ FIRST_PARAMETER_VALUE : 0|32@1+ (1,0) [0|0] "" Vector__XXX
 SG_ SECOND_PARAMETER_VALUE : 32|32@1+ (1,0) [0|0] "" Vector__XXX

CM_ BO_ 2181382336 "Read parameter 38 and 39 at the same time. SPARK MAX does not currently support this in v25.0.0-prerelease.4";
CM_ SG_ 2181382336 FIRST_PARAMETER_VALUE "The actual type of this data depends on the Parameter Type of the parameter in question";
CM_ SG_ 2181382336 SECOND_PARAMETER_VALUE "The actual type of this data depends on the Parameter Type of the parameter in question";

BO_ 2181382400 READ_PARAMETER_40_AND_41: 8 Vector__XXX
 SG_ FIRST_PARAMETER_VALUE : 0|32@1+ (1,0) [0|0] "" Vector__XXX
 SG_ SECOND_PARAMETER_VALUE : 32|32@1+ (1,0) [0|0] "" Vector__XXX

CM_ BO_ 2181382400 "Read parameter 40 and 41 at the same time. SPARK MAX does not currently support this in v25.0.0-prerelease.4";
CM_ SG_ 2181382400 FIRST_PARAMETER_VALUE "The actual type of this data depends on the Parameter Type of the parameter in question";
CM_ SG_ 2181382400 SECOND_PARAMETER_VALUE "The actual type of this data depends on the Parameter Type of the parameter in question";

BO_ 2181382464 READ_PARAMETER_42_AND_43: 8 Vector__XXX
 SG_ FIRST_PARAMETER_VALUE : 0|32@1+ (1,0) [0|0] "" Vector__XXX
 SG_ SECOND_PARAMETER_VALUE : 32|32@1+ (1,0) [0|0] "" Vector__XXX

CM_ BO_ 2181382464 "Read parameter 42 and 43 at the same time. SPARK MAX does not currently support this in v25.0.0-prerelease.4";
CM_ SG_ 2181382464 FIRST_PARAMETER_VALUE "The actual type of this data depends on the Parameter Type of the parameter in question";
CM_ SG_ 2181382464 SECOND_PARAMETER_VALUE "The actual type of this data depends on the Parameter Type of the parameter in question";

BO_ 2181382528 READ_PARAMETER_44_AND_45: 8 Vector__XXX
 SG_ FIRST_PARAMETER_VALUE : 0|32@1+ (1,0) [0|0] "" Vector__XXX
 SG_ SECOND_PARAMETER_VALUE : 32|32@1+ (1,0) [0|0] "" Vector__XXX

CM_ BO_ 2181382528 "Read parameter 44 and 45 at the same time. SPARK MAX does not currently support this in v25.0.0-prerelease.4";
CM_ SG_ 2181382528 FIRST_PARAMETER_VALUE "The actual type of this data depends on the Parameter Type of the parameter in question";
CM_ SG_ 2181382528 SECOND_PARAMETER_VALUE "The actual type of this data depends on the Parameter Type of the parameter in question";

BO_ 2181382592 READ_PARAMETER_46_AND_47: 8 Vector__XXX
 SG_ FIRST_PARAMETER_VALUE : 0|32@1+ (1,0) [0|0] "" Vector__XXX
 SG_ SECOND_PARAMETER_VALUE : 32|32@1+ (1,0) [0|0] "" Vector__XXX

CM_ BO_ 2181382592 "Read parameter 46 and 47 at the same time. SPARK MAX does not currently support this in v25.0.0-prerelease.4";
CM_ SG_ 2181382592 FIRST_PARAMETER_VALUE "The actual type of this data depends on the Parameter Type of the parameter in question";
CM_ SG_ 2181382592 SECOND_PARAMETER_VALUE "The actual type of this data depends on the Parameter Type of the parameter in question";

BO_ 2181382656 READ_PARAMETER_48_AND_49: 8 Vector__XXX
 SG_ FIRST_PARAMETER_VALUE : 0|32@1+ (1,0) [0|0] "" Vector__XXX
 SG_ SECOND_PARAMETER_VALUE : 32|32@1+ (1,0) [0|0] "" Vector__XXX

CM_ BO_ 2181382656 "Read parameter 48 and 49 at the same time. SPARK MAX does not currently support this in v25.0.0-prerelease.4";
CM_ SG_ 2181382656 FIRST_PARAMETER_VALUE "The actual type of this data depends on the Parameter Type of the parameter in question";
CM_ SG_ 2181382656 SECOND_PARAMETER_VALUE "The actual type of this data depends on the Parameter Type of the parameter in question";

BO_ 2181382720 READ_PARAMETER_50_AND_51: 8 Vector__XXX
 SG_ FIRST_PARAMETER_VALUE : 0|32@1+ (1,0) [0|0] "" Vector__XXX
 SG_ SECOND_PARAMETER_VALUE : 32|32@1+ (1,0) [0|0] "" Vector__XXX

CM_ BO_ 2181382720 "Read parameter 50 and 51 at the same time. SPARK MAX does not currently support this in v25.0.0-prerelease.4";
CM_ SG_ 2181382720 FIRST_PARAMETER_VALUE "The actual type of this data depends on the Parameter Type of the parameter in question";
CM_ SG_ 2181382720 SECOND_PARAMETER_VALUE "The actual type of this data depends on the Parameter Type of the parameter in question";

BO_ 2181382784 READ_PARAMETER_52_AND_53: 8 Vector__XXX
 SG_ FIRST_PARAMETER_VALUE : 0|32@1+ (1,0) [0|0] "" Vector__XXX
 SG_ SECOND_PARAMETER_VALUE : 32|32@1+ (1,0) [0|0] "" Vector__XXX

CM_ BO_ 2181382784 "Read parameter 52 and 53 at the same time. SPARK MAX does not currently support this in v25.0.0-prerelease.4";
CM_ SG_ 2181382784 FIRST_PARAMETER_VALUE "The actual type of this data depends on the Parameter Type of the parameter in question";
CM_ SG_ 2181382784 SECOND_PARAMETER_VALUE "The actual type of this data depends on the Parameter Type of the parameter in question";

BO_ 2181382848 READ_PARAMETER_54_AND_55: 8 Vector__XXX
 SG_ FIRST_PARAMETER_VALUE : 0|32@1+ (1,0) [0|0] "" Vector__XXX
 SG_ SECOND_PARAMETER_VALUE : 32|32@1+ (1,0) [0|0] "" Vector__XXX

CM_ BO_ 2181382848 "Read parameter 54 and 55 at the same time. SPARK MAX does not currently support this in v25.0.0-prerelease.4";
CM_ SG_ 2181382848 FIRST_PARAMETER_VALUE "The actual type of this data depends on the Parameter Type of the parameter in question";
CM_ SG_ 2181382848 SECOND_PARAMETER_VALUE "The actual type of this data depends on the Parameter Type of the parameter in question";

BO_ 2181382912 READ_PARAMETER_56_AND_57: 8 Vector__XXX
 SG_ FIRST_PARAMETER_VALUE : 0|32@1+ (1,0) [0|0] "" Vector__XXX
 SG_ SECOND_PARAMETER_VALUE : 32|32@1+ (1,0) [0|0] "" Vector__XXX

CM_ BO_ 2181382912 "Read parameter 56 and 57 at the same time. SPARK MAX does not currently support this in v25.0.0-prerelease.4";
CM_ SG_ 2181382912 FIRST_PARAMETER_VALUE "The actual type of this data depends on the Parameter Type of the parameter in question";
CM_ SG_ 2181382912 SECOND_PARAMETER_VALUE "The actual type of this data depends on the Parameter Type of the parameter in question";

BO_ 2181382976 READ_PARAMETER_58_AND_59: 8 Vector__XXX
 SG_ FIRST_PARAMETER_VALUE : 0|32@1+ (1,0) [0|0] "" Vector__XXX
 SG_ SECOND_PARAMETER_VALUE : 32|32@1+ (1,0) [0|0] "" Vector__XXX

CM_ BO_ 2181382976 "Read parameter 58 and 59 at the same time. SPARK MAX does not currently support this in v25.0.0-prerelease.4";
CM_ SG_ 2181382976 FIRST_PARAMETER_VALUE "The actual type of this data depends on the Parameter Type of the parameter in question";
CM_ SG_ 2181382976 SECOND_PARAMETER_VALUE "The actual type of this data depends on the Parameter Type of the parameter in question";

BO_ 2181383040 READ_PARAMETER_60_AND_61: 8 Vector__XXX
 SG_ FIRST_PARAMETER_VALUE : 0|32@1+ (1,0) [0|0] "" Vector__XXX
 SG_ SECOND_PARAMETER_VALUE : 32|32@1+ (1,0) [0|0] "" Vector__XXX

CM_ BO_ 2181383040 "Read parameter 60 and 61 at the same time. SPARK MAX does not currently support this in v25.0.0-prerelease.4";
CM_ SG_ 2181383040 FIRST_PARAMETER_VALUE "The actual type of this data depends on the Parameter Type of the parameter in question";
CM_ SG_ 2181383040 SECOND_PARAMETER_VALUE "The actual type of this data depends on the Parameter Type of the parameter in question";

BO_ 2181383104 READ_PARAMETER_62_AND_63: 8 Vector__XXX
 SG_ FIRST_PARAMETER_VALUE : 0|32@1+ (1,0) [0|0] "" Vector__XXX
 SG_ SECOND_PARAMETER_VALUE : 32|32@1+ (1,0) [0|0] "" Vector__XXX

CM_ BO_ 2181383104 "Read parameter 62 and 63 at the same time. SPARK MAX does not currently support this in v25.0.0-prerelease.4";
CM_ SG_ 2181383104 FIRST_PARAMETER_VALUE "The actual type of this data depends on the Parameter Type of the parameter in question";
CM_ SG_ 2181383104 SECOND_PARAMETER_VALUE "The actual type of this data depends on the Parameter Type of the parameter in question";

BO_ 2181383168 READ_PARAMETER_64_AND_65: 8 Vector__XXX
 SG_ FIRST_PARAMETER_VALUE : 0|32@1+ (1,0) [0|0] "" Vector__XXX
 SG_ SECOND_PARAMETER_VALUE : 32|32@1+ (1,0) [0|0] "" Vector__XXX

CM_ BO_ 2181383168 "Read parameter 64 and 65 at the same time. SPARK MAX does not currently support this in v25.0.0-prerelease.4";
CM_ SG_ 2181383168 FIRST_PARAMETER_VALUE "The actual type of this data depends on the Parameter Type of the parameter in question";
CM_ SG_ 2181383168 SECOND_PARAMETER_VALUE "The actual type of this data depends on the Parameter Type of the parameter in question";

BO_ 2181383232 READ_PARAMETER_66_AND_67: 8 Vector__XXX
 SG_ FIRST_PARAMETER_VALUE : 0|32@1+ (1,0) [0|0] "" Vector__XXX
 SG_ SECOND_PARAMETER_VALUE : 32|32@1+ (1,0) [0|0] "" Vector__XXX

CM_ BO_ 2181383232 "Read parameter 66 and 67 at the same time. SPARK MAX does not currently support this in v25.0.0-prerelease.4";
CM_ SG_ 2181383232 FIRST_PARAMETER_VALUE "The actual type of this data depends on the Parameter Type of the parameter in question";
CM_ SG_ 2181383232 SECOND_PARAMETER_VALUE "The actual type of this data depends on the Parameter Type of the parameter in question";

BO_ 2181383296 READ_PARAMETER_68_AND_69: 8 Vector__XXX
 SG_ FIRST_PARAMETER_VALUE : 0|32@1+ (1,0) [0|0] "" Vector__XXX
 SG_ SECOND_PARAMETER_VALUE : 32|32@1+ (1,0) [0|0] "" Vector__XXX

CM_ BO_ 2181383296 "Read parameter 68 and 69 at the same time. SPARK MAX does not currently support this in v25.0.0-prerelease.4";
CM_ SG_ 2181383296 FIRST_PARAMETER_VALUE "The actual type of this data depends on the Parameter Type of the parameter in question";
CM_ SG_ 2181383296 SECOND_PARAMETER_VALUE "The actual type of this data depends on the Parameter Type of the parameter in question";

BO_ 2181383360 READ_PARAMETER_70_AND_71: 8 Vector__XXX
 SG_ FIRST_PARAMETER_VALUE : 0|32@1+ (1,0) [0|0] "" Vector__XXX
 SG_ SECOND_PARAMETER_VALUE : 32|32@1+ (1,0) [0|0] "" Vector__XXX

CM_ BO_ 2181383360 "Read parameter 70 and 71 at the same time. SPARK MAX does not currently support this in v25.0.0-prerelease.4";
CM_ SG_ 2181383360 FIRST_PARAMETER_VALUE "The actual type of this data depends on the Parameter Type of the parameter in question";
CM_ SG_ 2181383360 SECOND_PARAMETER_VALUE "The actual type of this data depends on the Parameter Type of the parameter in question";

BO_ 2181383424 READ_PARAMETER_72_AND_73: 8 Vector__XXX
 SG_ FIRST_PARAMETER_VALUE : 0|32@1+ (1,0) [0|0] "" Vector__XXX
 SG_ SECOND_PARAMETER_VALUE : 32|32@1+ (1,0) [0|0] "" Vector__XXX

CM_ BO_ 2181383424 "Read parameter 72 and 73 at the same time. SPARK MAX does not currently support this in v25.0.0-prerelease.4";
CM_ SG_ 2181383424 FIRST_PARAMETER_VALUE "The actual type of this data depends on the Parameter Type of the parameter in question";
CM_ SG_ 2181383424 SECOND_PARAMETER_VALUE "The actual type of this data depends on the Parameter Type of the parameter in question";

BO_ 2181383488 READ_PARAMETER_74_AND_75: 8 Vector__XXX
 SG_ FIRST_PARAMETER_VALUE : 0|32@1+ (1,0) [0|0] "" Vector__XXX
 SG_ SECOND_PARAMETER_VALUE : 32|32@1+ (1,0) [0|0] "" Vector__XXX

CM_ BO_ 2181383488 "Read parameter 74 and 75 at the same time. SPARK MAX does not currently support this in v25.0.0-prerelease.4";
CM_ SG_ 2181383488 FIRST_PARAMETER_VALUE "The actual type of this data depends on the Parameter Type of the parameter in question";
CM_ SG_ 2181383488 SECOND_PARAMETER_VALUE "The actual type of this data depends on the Parameter Type of the parameter in question";

BO_ 2181383552 READ_PARAMETER_76_AND_77: 8 Vector__XXX
 SG_ FIRST_PARAMETER_VALUE : 0|32@1+ (1,0) [0|0] "" Vector__XXX
 SG_ SECOND_PARAMETER_VALUE : 32|32@1+ (1,0) [0|0] "" Vector__XXX

CM_ BO_ 2181383552 "Read parameter 76 and 77 at the same time. SPARK MAX does not currently support this in v25.0.0-prerelease.4";
CM_ SG_ 2181383552 FIRST_PARAMETER_VALUE "The actual type of this data depends on the Parameter Type of the parameter in question";
CM_ SG_ 2181383552 SECOND_PARAMETER_VALUE "The actual type of this data depends on the Parameter Type of the parameter in question";

BO_ 2181383616 READ_PARAMETER_78_AND_79: 8 Vector__XXX
 SG_ FIRST_PARAMETER_VALUE : 0|32@1+ (1,0) [0|0] "" Vector__XXX
 SG_ SECOND_PARAMETER_VALUE : 32|32@1+ (1,0) [0|0] "" Vector__XXX

CM_ BO_ 2181383616 "Read parameter 78 and 79 at the same time. SPARK MAX does not currently support this in v25.0.0-prerelease.4";
CM_ SG_ 2181383616 FIRST_PARAMETER_VALUE "The actual type of this data depends on the Parameter Type of the parameter in question";
CM_ SG_ 2181383616 SECOND_PARAMETER_VALUE "The actual type of this data depends on the Parameter Type of the parameter in question";

BO_ 2181383680 READ_PARAMETER_80_AND_81: 8 Vector__XXX
 SG_ FIRST_PARAMETER_VALUE : 0|32@1+ (1,0) [0|0] "" Vector__XXX
 SG_ SECOND_PARAMETER_VALUE : 32|32@1+ (1,0) [0|0] "" Vector__XXX

CM_ BO_ 2181383680 "Read parameter 80 and 81 at the same time. SPARK MAX does not currently support this in v25.0.0-prerelease.4";
CM_ SG_ 2181383680 FIRST_PARAMETER_VALUE "The actual type of this data depends on the Parameter Type of the parameter in question";
CM_ SG_ 2181383680 SECOND_PARAMETER_VALUE "The actual type of this data depends on the Parameter Type of the parameter in question";

BO_ 2181383744 READ_PARAMETER_82_AND_83: 8 Vector__XXX
 SG_ FIRST_PARAMETER_VALUE : 0|32@1+ (1,0) [0|0] "" Vector__XXX
 SG_ SECOND_PARAMETER_VALUE : 32|32@1+ (1,0) [0|0] "" Vector__XXX

CM_ BO_ 2181383744 "Read parameter 82 and 83 at the same time. SPARK MAX does not currently support this in v25.0.0-prerelease.4";
CM_ SG_ 2181383744 FIRST_PARAMETER_VALUE "The actual type of this data depends on the Parameter Type of the parameter in question";
CM_ SG_ 2181383744 SECOND_PARAMETER_VALUE "The actual type of this data depends on the Parameter Type of the parameter in question";

BO_ 2181383808 READ_PARAMETER_84_AND_85: 8 Vector__XXX
 SG_ FIRST_PARAMETER_VALUE : 0|32@1+ (1,0) [0|0] "" Vector__XXX
 SG_ SECOND_PARAMETER_VALUE : 32|32@1+ (1,0) [0|0] "" Vector__XXX

CM_ BO_ 2181383808 "Read parameter 84 and 85 at the same time. SPARK MAX does not currently support this in v25.0.0-prerelease.4";
CM_ SG_ 2181383808 FIRST_PARAMETER_VALUE "The actual type of this data depends on the Parameter Type of the parameter in question";
CM_ SG_ 2181383808 SECOND_PARAMETER_VALUE "The actual type of this data depends on the Parameter Type of the parameter in question";

BO_ 2181383872 READ_PARAMETER_86_AND_87: 8 Vector__XXX
 SG_ FIRST_PARAMETER_VALUE : 0|32@1+ (1,0) [0|0] "" Vector__XXX
 SG_ SECOND_PARAMETER_VALUE : 32|32@1+ (1,0) [0|0] "" Vector__XXX

CM_ BO_ 2181383872 "Read parameter 86 and 87 at the same time. SPARK MAX does not currently support this in v25.0.0-prerelease.4";
CM_ SG_ 2181383872 FIRST_PARAMETER_VALUE "The actual type of this data depends on the Parameter Type of the parameter in question";
CM_ SG_ 2181383872 SECOND_PARAMETER_VALUE "The actual type of this data depends on the Parameter Type of the parameter in question";

BO_ 2181383936 READ_PARAMETER_88_AND_89: 8 Vector__XXX
 SG_ FIRST_PARAMETER_VALUE : 0|32@1+ (1,0) [0|0] "" Vector__XXX
 SG_ SECOND_PARAMETER_VALUE : 32|32@1+ (1,0) [0|0] "" Vector__XXX

CM_ BO_ 2181383936 "Read parameter 88 and 89 at the same time. SPARK MAX does not currently support this in v25.0.0-prerelease.4";
CM_ SG_ 2181383936 FIRST_PARAMETER_VALUE "The actual type of this data depends on the Parameter Type of the parameter in question";
CM_ SG_ 2181383936 SECOND_PARAMETER_VALUE "The actual type of this data depends on the Parameter Type of the parameter in question";

BO_ 2181384000 READ_PARAMETER_90_AND_91: 8 Vector__XXX
 SG_ FIRST_PARAMETER_VALUE : 0|32@1+ (1,0) [0|0] "" Vector__XXX
 SG_ SECOND_PARAMETER_VALUE : 32|32@1+ (1,0) [0|0] "" Vector__XXX

CM_ BO_ 2181384000 "Read parameter 90 and 91 at the same time. SPARK MAX does not currently support this in v25.0.0-prerelease.4";
CM_ SG_ 2181384000 FIRST_PARAMETER_VALUE "The actual type of this data depends on the Parameter Type of the parameter in question";
CM_ SG_ 2181384000 SECOND_PARAMETER_VALUE "The actual type of this data depends on the Parameter Type of the parameter in question";

BO_ 2181384064 READ_PARAMETER_92_AND_93: 8 Vector__XXX
 SG_ FIRST_PARAMETER_VALUE : 0|32@1+ (1,0) [0|0] "" Vector__XXX
 SG_ SECOND_PARAMETER_VALUE : 32|32@1+ (1,0) [0|0] "" Vector__XXX

CM_ BO_ 2181384064 "Read parameter 92 and 93 at the same time. SPARK MAX does not currently support this in v25.0.0-prerelease.4";
CM_ SG_ 2181384064 FIRST_PARAMETER_VALUE "The actual type of this data depends on the Parameter Type of the parameter in question";
CM_ SG_ 2181384064 SECOND_PARAMETER_VALUE "The actual type of this data depends on the Parameter Type of the parameter in question";

BO_ 2181384128 READ_PARAMETER_94_AND_95: 8 Vector__XXX
 SG_ FIRST_PARAMETER_VALUE : 0|32@1+ (1,0) [0|0] "" Vector__XXX
 SG_ SECOND_PARAMETER_VALUE : 32|32@1+ (1,0) [0|0] "" Vector__XXX

CM_ BO_ 2181384128 "Read parameter 94 and 95 at the same time. SPARK MAX does not currently support this in v25.0.0-prerelease.4";
CM_ SG_ 2181384128 FIRST_PARAMETER_VALUE "The actual type of this data depends on the Parameter Type of the parameter in question";
CM_ SG_ 2181384128 SECOND_PARAMETER_VALUE "The actual type of this data depends on the Parameter Type of the parameter in question";

BO_ 2181384192 READ_PARAMETER_96_AND_97: 8 Vector__XXX
 SG_ FIRST_PARAMETER_VALUE : 0|32@1+ (1,0) [0|0] "" Vector__XXX
 SG_ SECOND_PARAMETER_VALUE : 32|32@1+ (1,0) [0|0] "" Vector__XXX

CM_ BO_ 2181384192 "Read parameter 96 and 97 at the same time. SPARK MAX does not currently support this in v25.0.0-prerelease.4";
CM_ SG_ 2181384192 FIRST_PARAMETER_VALUE "The actual type of this data depends on the Parameter Type of the parameter in question";
CM_ SG_ 2181384192 SECOND_PARAMETER_VALUE "The actual type of this data depends on the Parameter Type of the parameter in question";

BO_ 2181384256 READ_PARAMETER_98_AND_99: 8 Vector__XXX
 SG_ FIRST_PARAMETER_VALUE : 0|32@1+ (1,0) [0|0] "" Vector__XXX
 SG_ SECOND_PARAMETER_VALUE : 32|32@1+ (1,0) [0|0] "" Vector__XXX

CM_ BO_ 2181384256 "Read parameter 98 and 99 at the same time. SPARK MAX does not currently support this in v25.0.0-prerelease.4";
CM_ SG_ 2181384256 FIRST_PARAMETER_VALUE "The actual type of this data depends on the Parameter Type of the parameter in question";
CM_ SG_ 2181384256 SECOND_PARAMETER_VALUE "The actual type of this data depends on the Parameter Type of the parameter in question";

BO_ 2181384320 READ_PARAMETER_100_AND_101: 8 Vector__XXX
 SG_ FIRST_PARAMETER_VALUE : 0|32@1+ (1,0) [0|0] "" Vector__XXX
 SG_ SECOND_PARAMETER_VALUE : 32|32@1+ (1,0) [0|0] "" Vector__XXX

CM_ BO_ 2181384320 "Read parameter 100 and 101 at the same time. SPARK MAX does not currently support this in v25.0.0-prerelease.4";
CM_ SG_ 2181384320 FIRST_PARAMETER_VALUE "The actual type of this data depends on the Parameter Type of the parameter in question";
CM_ SG_ 2181384320 SECOND_PARAMETER_VALUE "The actual type of this data depends on the Parameter Type of the parameter in question";

BO_ 2181384384 READ_PARAMETER_102_AND_103: 8 Vector__XXX
 SG_ FIRST_PARAMETER_VALUE : 0|32@1+ (1,0) [0|0] "" Vector__XXX
 SG_ SECOND_PARAMETER_VALUE : 32|32@1+ (1,0) [0|0] "" Vector__XXX

CM_ BO_ 2181384384 "Read parameter 102 and 103 at the same time. SPARK MAX does not currently support this in v25.0.0-prerelease.4";
CM_ SG_ 2181384384 FIRST_PARAMETER_VALUE "The actual type of this data depends on the Parameter Type of the parameter in question";
CM_ SG_ 2181384384 SECOND_PARAMETER_VALUE "The actual type of this data depends on the Parameter Type of the parameter in question";

BO_ 2181384448 READ_PARAMETER_104_AND_105: 8 Vector__XXX
 SG_ FIRST_PARAMETER_VALUE : 0|32@1+ (1,0) [0|0] "" Vector__XXX
 SG_ SECOND_PARAMETER_VALUE : 32|32@1+ (1,0) [0|0] "" Vector__XXX

CM_ BO_ 2181384448 "Read parameter 104 and 105 at the same time. SPARK MAX does not currently support this in v25.0.0-prerelease.4";
CM_ SG_ 2181384448 FIRST_PARAMETER_VALUE "The actual type of this data depends on the Parameter Type of the parameter in question";
CM_ SG_ 2181384448 SECOND_PARAMETER_VALUE "The actual type of this data depends on the Parameter Type of the parameter in question";

BO_ 2181384512 READ_PARAMETER_106_AND_107: 8 Vector__XXX
 SG_ FIRST_PARAMETER_VALUE : 0|32@1+ (1,0) [0|0] "" Vector__XXX
 SG_ SECOND_PARAMETER_VALUE : 32|32@1+ (1,0) [0|0] "" Vector__XXX

CM_ BO_ 2181384512 "Read parameter 106 and 107 at the same time. SPARK MAX does not currently support this in v25.0.0-prerelease.4";
CM_ SG_ 2181384512 FIRST_PARAMETER_VALUE "The actual type of this data depends on the Parameter Type of the parameter in question";
CM_ SG_ 2181384512 SECOND_PARAMETER_VALUE "The actual type of this data depends on the Parameter Type of the parameter in question";

BO_ 2181384576 READ_PARAMETER_108_AND_109: 8 Vector__XXX
 SG_ FIRST_PARAMETER_VALUE : 0|32@1+ (1,0) [0|0] "" Vector__XXX
 SG_ SECOND_PARAMETER_VALUE : 32|32@1+ (1,0) [0|0] "" Vector__XXX

CM_ BO_ 2181384576 "Read parameter 108 and 109 at the same time. SPARK MAX does not currently support this in v25.0.0-prerelease.4";
CM_ SG_ 2181384576 FIRST_PARAMETER_VALUE "The actual type of this data depends on the Parameter Type of the parameter in question";
CM_ SG_ 2181384576 SECOND_PARAMETER_VALUE "The actual type of this data depends on the Parameter Type of the parameter in question";

BO_ 2181384640 READ_PARAMETER_110_AND_111: 8 Vector__XXX
 SG_ FIRST_PARAMETER_VALUE : 0|32@1+ (1,0) [0|0] "" Vector__XXX
 SG_ SECOND_PARAMETER_VALUE : 32|32@1+ (1,0) [0|0] "" Vector__XXX

CM_ BO_ 2181384640 "Read parameter 110 and 111 at the same time. SPARK MAX does not currently support this in v25.0.0-prerelease.4";
CM_ SG_ 2181384640 FIRST_PARAMETER_VALUE "The actual type of this data depends on the Parameter Type of the parameter in question";
CM_ SG_ 2181384640 SECOND_PARAMETER_VALUE "The actual type of this data depends on the Parameter Type of the parameter in question";

BO_ 2181384704 READ_PARAMETER_112_AND_113: 8 Vector__XXX
 SG_ FIRST_PARAMETER_VALUE : 0|32@1+ (1,0) [0|0] "" Vector__XXX
 SG_ SECOND_PARAMETER_VALUE : 32|32@1+ (1,0) [0|0] "" Vector__XXX

CM_ BO_ 2181384704 "Read parameter 112 and 113 at the same time. SPARK MAX does not currently support this in v25.0.0-prerelease.4";
CM_ SG_ 2181384704 FIRST_PARAMETER_VALUE "The actual type of this data depends on the Parameter Type of the parameter in question";
CM_ SG_ 2181384704 SECOND_PARAMETER_VALUE "The actual type of this data depends on the Parameter Type of the parameter in question";

BO_ 2181384768 READ_PARAMETER_114_AND_115: 8 Vector__XXX
 SG_ FIRST_PARAMETER_VALUE : 0|32@1+ (1,0) [0|0] "" Vector__XXX
 SG_ SECOND_PARAMETER_VALUE : 32|32@1+ (1,0) [0|0] "" Vector__XXX

CM_ BO_ 2181384768 "Read parameter 114 and 115 at the same time. SPARK MAX does not currently support this in v25.0.0-prerelease.4";
CM_ SG_ 2181384768 FIRST_PARAMETER_VALUE "The actual type of this data depends on the Parameter Type of the parameter in question";
CM_ SG_ 2181384768 SECOND_PARAMETER_VALUE "The actual type of this data depends on the Parameter Type of the parameter in question";

BO_ 2181384832 READ_PARAMETER_116_AND_117: 8 Vector__XXX
 SG_ FIRST_PARAMETER_VALUE : 0|32@1+ (1,0) [0|0] "" Vector__XXX
 SG_ SECOND_PARAMETER_VALUE : 32|32@1+ (1,0) [0|0] "" Vector__XXX

CM_ BO_ 2181384832 "Read parameter 116 and 117 at the same time. SPARK MAX does not currently support this in v25.0.0-prerelease.4";
CM_ SG_ 2181384832 FIRST_PARAMETER_VALUE "The actual type of this data depends on the Parameter Type of the parameter in question";
CM_ SG_ 2181384832 SECOND_PARAMETER_VALUE "The actual type of this data depends on the Parameter Type of the parameter in question";

BO_ 2181384896 READ_PARAMETER_118_AND_119: 8 Vector__XXX
 SG_ FIRST_PARAMETER_VALUE : 0|32@1+ (1,0) [0|0] "" Vector__XXX
 SG_ SECOND_PARAMETER_VALUE : 32|32@1+ (1,0) [0|0] "" Vector__XXX

CM_ BO_ 2181384896 "Read parameter 118 and 119 at the same time. SPARK MAX does not currently support this in v25.0.0-prerelease.4";
CM_ SG_ 2181384896 FIRST_PARAMETER_VALUE "The actual type of this data depends on the Parameter Type of the parameter in question";
CM_ SG_ 2181384896 SECOND_PARAMETER_VALUE "The actual type of this data depends on the Parameter Type of the parameter in question";

BO_ 2181384960 READ_PARAMETER_120_AND_121: 8 Vector__XXX
 SG_ FIRST_PARAMETER_VALUE : 0|32@1+ (1,0) [0|0] "" Vector__XXX
 SG_ SECOND_PARAMETER_VALUE : 32|32@1+ (1,0) [0|0] "" Vector__XXX

CM_ BO_ 2181384960 "Read parameter 120 and 121 at the same time. SPARK MAX does not currently support this in v25.0.0-prerelease.4";
CM_ SG_ 2181384960 FIRST_PARAMETER_VALUE "The actual type of this data depends on the Parameter Type of the parameter in question";
CM_ SG_ 2181384960 SECOND_PARAMETER_VALUE "The actual type of this data depends on the Parameter Type of the parameter in question";

BO_ 2181385024 READ_PARAMETER_122_AND_123: 8 Vector__XXX
 SG_ FIRST_PARAMETER_VALUE : 0|32@1+ (1,0) [0|0] "" Vector__XXX
 SG_ SECOND_PARAMETER_VALUE : 32|32@1+ (1,0) [0|0] "" Vector__XXX

CM_ BO_ 2181385024 "Read parameter 122 and 123 at the same time. SPARK MAX does not currently support this in v25.0.0-prerelease.4";
CM_ SG_ 2181385024 FIRST_PARAMETER_VALUE "The actual type of this data depends on the Parameter Type of the parameter in question";
CM_ SG_ 2181385024 SECOND_PARAMETER_VALUE "The actual type of this data depends on the Parameter Type of the parameter in question";

BO_ 2181385088 READ_PARAMETER_124_AND_125: 8 Vector__XXX
 SG_ FIRST_PARAMETER_VALUE : 0|32@1+ (1,0) [0|0] "" Vector__XXX
 SG_ SECOND_PARAMETER_VALUE : 32|32@1+ (1,0) [0|0] "" Vector__XXX

CM_ BO_ 2181385088 "Read parameter 124 and 125 at the same time. SPARK MAX does not currently support this in v25.0.0-prerelease.4";
CM_ SG_ 2181385088 FIRST_PARAMETER_VALUE "The actual type of this data depends on the Parameter Type of the parameter in question";
CM_ SG_ 2181385088 SECOND_PARAMETER_VALUE "The actual type of this data depends on the Parameter Type of the parameter in question";

BO_ 2181385152 READ_PARAMETER_126_AND_127: 8 Vector__XXX
 SG_ FIRST_PARAMETER_VALUE : 0|32@1+ (1,0) [0|0] "" Vector__XXX
 SG_ SECOND_PARAMETER_VALUE : 32|32@1+ (1,0) [0|0] "" Vector__XXX

CM_ BO_ 2181385152 "Read parameter 126 and 127 at the same time. SPARK MAX does not currently support this in v25.0.0-prerelease.4";
CM_ SG_ 2181385152 FIRST_PARAMETER_VALUE "The actual type of this data depends on the Parameter Type of the parameter in question";
CM_ SG_ 2181385152 SECOND_PARAMETER_VALUE "The actual type of this data depends on the Parameter Type of the parameter in question";

BO_ 2181385216 READ_PARAMETER_128_AND_129: 8 Vector__XXX
 SG_ FIRST_PARAMETER_VALUE : 0|32@1+ (1,0) [0|0] "" Vector__XXX
 SG_ SECOND_PARAMETER_VALUE : 32|32@1+ (1,0) [0|0] "" Vector__XXX

CM_ BO_ 2181385216 "Read parameter 128 and 129 at the same time. SPARK MAX does not currently support this in v25.0.0-prerelease.4";
CM_ SG_ 2181385216 FIRST_PARAMETER_VALUE "The actual type of this data depends on the Parameter Type of the parameter in question";
CM_ SG_ 2181385216 SECOND_PARAMETER_VALUE "The actual type of this data depends on the Parameter Type of the parameter in question";

BO_ 2181385280 READ_PARAMETER_130_AND_131: 8 Vector__XXX
 SG_ FIRST_PARAMETER_VALUE : 0|32@1+ (1,0) [0|0] "" Vector__XXX
 SG_ SECOND_PARAMETER_VALUE : 32|32@1+ (1,0) [0|0] "" Vector__XXX

CM_ BO_ 2181385280 "Read parameter 130 and 131 at the same time. SPARK MAX does not currently support this in v25.0.0-prerelease.4";
CM_ SG_ 2181385280 FIRST_PARAMETER_VALUE "The actual type of this data depends on the Parameter Type of the parameter in question";
CM_ SG_ 2181385280 SECOND_PARAMETER_VALUE "The actual type of this data depends on the Parameter Type of the parameter in question";

BO_ 2181385344 READ_PARAMETER_132_AND_133: 8 Vector__XXX
 SG_ FIRST_PARAMETER_VALUE : 0|32@1+ (1,0) [0|0] "" Vector__XXX
 SG_ SECOND_PARAMETER_VALUE : 32|32@1+ (1,0) [0|0] "" Vector__XXX

CM_ BO_ 2181385344 "Read parameter 132 and 133 at the same time. SPARK MAX does not currently support this in v25.0.0-prerelease.4";
CM_ SG_ 2181385344 FIRST_PARAMETER_VALUE "The actual type of this data depends on the Parameter Type of the parameter in question";
CM_ SG_ 2181385344 SECOND_PARAMETER_VALUE "The actual type of this data depends on the Parameter Type of the parameter in question";

BO_ 2181385408 READ_PARAMETER_134_AND_135: 8 Vector__XXX
 SG_ FIRST_PARAMETER_VALUE : 0|32@1+ (1,0) [0|0] "" Vector__XXX
 SG_ SECOND_PARAMETER_VALUE : 32|32@1+ (1,0) [0|0] "" Vector__XXX

CM_ BO_ 2181385408 "Read parameter 134 and 135 at the same time. SPARK MAX does not currently support this in v25.0.0-prerelease.4";
CM_ SG_ 2181385408 FIRST_PARAMETER_VALUE "The actual type of this data depends on the Parameter Type of the parameter in question";
CM_ SG_ 2181385408 SECOND_PARAMETER_VALUE "The actual type of this data depends on the Parameter Type of the parameter in question";

BO_ 2181385472 READ_PARAMETER_136_AND_137: 8 Vector__XXX
 SG_ FIRST_PARAMETER_VALUE : 0|32@1+ (1,0) [0|0] "" Vector__XXX
 SG_ SECOND_PARAMETER_VALUE : 32|32@1+ (1,0) [0|0] "" Vector__XXX

CM_ BO_ 2181385472 "Read parameter 136 and 137 at the same time. SPARK MAX does not currently support this in v25.0.0-prerelease.4";
CM_ SG_ 2181385472 FIRST_PARAMETER_VALUE "The actual type of this data depends on the Parameter Type of the parameter in question";
CM_ SG_ 2181385472 SECOND_PARAMETER_VALUE "The actual type of this data depends on the Parameter Type of the parameter in question";

BO_ 2181385536 READ_PARAMETER_138_AND_139: 8 Vector__XXX
 SG_ FIRST_PARAMETER_VALUE : 0|32@1+ (1,0) [0|0] "" Vector__XXX
 SG_ SECOND_PARAMETER_VALUE : 32|32@1+ (1,0) [0|0] "" Vector__XXX

CM_ BO_ 2181385536 "Read parameter 138 and 139 at the same time. SPARK MAX does not currently support this in v25.0.0-prerelease.4";
CM_ SG_ 2181385536 FIRST_PARAMETER_VALUE "The actual type of this data depends on the Parameter Type of the parameter in question";
CM_ SG_ 2181385536 SECOND_PARAMETER_VALUE "The actual type of this data depends on the Parameter Type of the parameter in question";

BO_ 2181385600 READ_PARAMETER_140_AND_141: 8 Vector__XXX
 SG_ FIRST_PARAMETER_VALUE : 0|32@1+ (1,0) [0|0] "" Vector__XXX
 SG_ SECOND_PARAMETER_VALUE : 32|32@1+ (1,0) [0|0] "" Vector__XXX

CM_ BO_ 2181385600 "Read parameter 140 and 141 at the same time. SPARK MAX does not currently support this in v25.0.0-prerelease.4";
CM_ SG_ 2181385600 FIRST_PARAMETER_VALUE "The actual type of this data depends on the Parameter Type of the parameter in question";
CM_ SG_ 2181385600 SECOND_PARAMETER_VALUE "The actual type of this data depends on the Parameter Type of the parameter in question";

BO_ 2181385664 READ_PARAMETER_142_AND_143: 8 Vector__XXX
 SG_ FIRST_PARAMETER_VALUE : 0|32@1+ (1,0) [0|0] "" Vector__XXX
 SG_ SECOND_PARAMETER_VALUE : 32|32@1+ (1,0) [0|0] "" Vector__XXX

CM_ BO_ 2181385664 "Read parameter 142 and 143 at the same time. SPARK MAX does not currently support this in v25.0.0-prerelease.4";
CM_ SG_ 2181385664 FIRST_PARAMETER_VALUE "The actual type of this data depends on the Parameter Type of the parameter in question";
CM_ SG_ 2181385664 SECOND_PARAMETER_VALUE "The actual type of this data depends on the Parameter Type of the parameter in question";

BO_ 2181385728 READ_PARAMETER_144_AND_145: 8 Vector__XXX
 SG_ FIRST_PARAMETER_VALUE : 0|32@1+ (1,0) [0|0] "" Vector__XXX
 SG_ SECOND_PARAMETER_VALUE : 32|32@1+ (1,0) [0|0] "" Vector__XXX

CM_ BO_ 2181385728 "Read parameter 144 and 145 at the same time. SPARK MAX does not currently support this in v25.0.0-prerelease.4";
CM_ SG_ 2181385728 FIRST_PARAMETER_VALUE "The actual type of this data depends on the Parameter Type of the parameter in question";
CM_ SG_ 2181385728 SECOND_PARAMETER_VALUE "The actual type of this data depends on the Parameter Type of the parameter in question";

BO_ 2181385792 READ_PARAMETER_146_AND_147: 8 Vector__XXX
 SG_ FIRST_PARAMETER_VALUE : 0|32@1+ (1,0) [0|0] "" Vector__XXX
 SG_ SECOND_PARAMETER_VALUE : 32|32@1+ (1,0) [0|0] "" Vector__XXX

CM_ BO_ 2181385792 "Read parameter 146 and 147 at the same time. SPARK MAX does not currently support this in v25.0.0-prerelease.4";
CM_ SG_ 2181385792 FIRST_PARAMETER_VALUE "The actual type of this data depends on the Parameter Type of the parameter in question";
CM_ SG_ 2181385792 SECOND_PARAMETER_VALUE "The actual type of this data depends on the Parameter Type of the parameter in question";

BO_ 2181385856 READ_PARAMETER_148_AND_149: 8 Vector__XXX
 SG_ FIRST_PARAMETER_VALUE : 0|32@1+ (1,0) [0|0] "" Vector__XXX
 SG_ SECOND_PARAMETER_VALUE : 32|32@1+ (1,0) [0|0] "" Vector__XXX

CM_ BO_ 2181385856 "Read parameter 148 and 149 at the same time. SPARK MAX does not currently support this in v25.0.0-prerelease.4";
CM_ SG_ 2181385856 FIRST_PARAMETER_VALUE "The actual type of this data depends on the Parameter Type of the parameter in question";
CM_ SG_ 2181385856 SECOND_PARAMETER_VALUE "The actual type of this data depends on the Parameter Type of the parameter in question";

BO_ 2181385920 READ_PARAMETER_150_AND_151: 8 Vector__XXX
 SG_ FIRST_PARAMETER_VALUE : 0|32@1+ (1,0) [0|0] "" Vector__XXX
 SG_ SECOND_PARAMETER_VALUE : 32|32@1+ (1,0) [0|0] "" Vector__XXX

CM_ BO_ 2181385920 "Read parameter 150 and 151 at the same time. SPARK MAX does not currently support this in v25.0.0-prerelease.4";
CM_ SG_ 2181385920 FIRST_PARAMETER_VALUE "The actual type of this data depends on the Parameter Type of the parameter in question";
CM_ SG_ 2181385920 SECOND_PARAMETER_VALUE "The actual type of this data depends on the Parameter Type of the parameter in question";

BO_ 2181385984 READ_PARAMETER_152_AND_153: 8 Vector__XXX
 SG_ FIRST_PARAMETER_VALUE : 0|32@1+ (1,0) [0|0] "" Vector__XXX
 SG_ SECOND_PARAMETER_VALUE : 32|32@1+ (1,0) [0|0] "" Vector__XXX

CM_ BO_ 2181385984 "Read parameter 152 and 153 at the same time. SPARK MAX does not currently support this in v25.0.0-prerelease.4";
CM_ SG_ 2181385984 FIRST_PARAMETER_VALUE "The actual type of this data depends on the Parameter Type of the parameter in question";
CM_ SG_ 2181385984 SECOND_PARAMETER_VALUE "The actual type of this data depends on the Parameter Type of the parameter in question";

BO_ 2181386048 READ_PARAMETER_154_AND_155: 8 Vector__XXX
 SG_ FIRST_PARAMETER_VALUE : 0|32@1+ (1,0) [0|0] "" Vector__XXX
 SG_ SECOND_PARAMETER_VALUE : 32|32@1+ (1,0) [0|0] "" Vector__XXX

CM_ BO_ 2181386048 "Read parameter 154 and 155 at the same time. SPARK MAX does not currently support this in v25.0.0-prerelease.4";
CM_ SG_ 2181386048 FIRST_PARAMETER_VALUE "The actual type of this data depends on the Parameter Type of the parameter in question";
CM_ SG_ 2181386048 SECOND_PARAMETER_VALUE "The actual type of this data depends on the Parameter Type of the parameter in question";

BO_ 2181386112 READ_PARAMETER_156_AND_157: 8 Vector__XXX
 SG_ FIRST_PARAMETER_VALUE : 0|32@1+ (1,0) [0|0] "" Vector__XXX
 SG_ SECOND_PARAMETER_VALUE : 32|32@1+ (1,0) [0|0] "" Vector__XXX

CM_ BO_ 2181386112 "Read parameter 156 and 157 at the same time. SPARK MAX does not currently support this in v25.0.0-prerelease.4";
CM_ SG_ 2181386112 FIRST_PARAMETER_VALUE "The actual type of this data depends on the Parameter Type of the parameter in question";
CM_ SG_ 2181386112 SECOND_PARAMETER_VALUE "The actual type of this data depends on the Parameter Type of the parameter in question";

BO_ 2181386176 READ_PARAMETER_158_AND_159: 8 Vector__XXX
 SG_ FIRST_PARAMETER_VALUE : 0|32@1+ (1,0) [0|0] "" Vector__XXX
 SG_ SECOND_PARAMETER_VALUE : 32|32@1+ (1,0) [0|0] "" Vector__XXX

CM_ BO_ 2181386176 "Read parameter 158 and 159 at the same time. SPARK MAX does not currently support this in v25.0.0-prerelease.4";
CM_ SG_ 2181386176 FIRST_PARAMETER_VALUE "The actual type of this data depends on the Parameter Type of the parameter in question";
CM_ SG_ 2181386176 SECOND_PARAMETER_VALUE "The actual type of this data depends on the Parameter Type of the parameter in question";

BO_ 2181386240 READ_PARAMETER_160_AND_161: 8 Vector__XXX
 SG_ FIRST_PARAMETER_VALUE : 0|32@1+ (1,0) [0|0] "" Vector__XXX
 SG_ SECOND_PARAMETER_VALUE : 32|32@1+ (1,0) [0|0] "" Vector__XXX

CM_ BO_ 2181386240 "Read parameter 160 and 161 at the same time. SPARK MAX does not currently support this in v25.0.0-prerelease.4";
CM_ SG_ 2181386240 FIRST_PARAMETER_VALUE "The actual type of this data depends on the Parameter Type of the parameter in question";
CM_ SG_ 2181386240 SECOND_PARAMETER_VALUE "The actual type of this data depends on the Parameter Type of the parameter in question";

BO_ 2181386304 READ_PARAMETER_162_AND_163: 8 Vector__XXX
 SG_ FIRST_PARAMETER_VALUE : 0|32@1+ (1,0) [0|0] "" Vector__XXX
 SG_ SECOND_PARAMETER_VALUE : 32|32@1+ (1,0) [0|0] "" Vector__XXX

CM_ BO_ 2181386304 "Read parameter 162 and 163 at the same time. SPARK MAX does not currently support this in v25.0.0-prerelease.4";
CM_ SG_ 2181386304 FIRST_PARAMETER_VALUE "The actual type of this data depends on the Parameter Type of the parameter in question";
CM_ SG_ 2181386304 SECOND_PARAMETER_VALUE "The actual type of this data depends on the Parameter Type of the parameter in question";

BO_ 2181386368 READ_PARAMETER_164_AND_165: 8 Vector__XXX
 SG_ FIRST_PARAMETER_VALUE : 0|32@1+ (1,0) [0|0] "" Vector__XXX
 SG_ SECOND_PARAMETER_VALUE : 32|32@1+ (1,0) [0|0] "" Vector__XXX

CM_ BO_ 2181386368 "Read parameter 164 and 165 at the same time. SPARK MAX does not currently support this in v25.0.0-prerelease.4";
CM_ SG_ 2181386368 FIRST_PARAMETER_VALUE "The actual type of this data depends on the Parameter Type of the parameter in question";
CM_ SG_ 2181386368 SECOND_PARAMETER_VALUE "The actual type of this data depends on the Parameter Type of the parameter in question";

BO_ 2181386432 READ_PARAMETER_166_AND_167: 8 Vector__XXX
 SG_ FIRST_PARAMETER_VALUE : 0|32@1+ (1,0) [0|0] "" Vector__XXX
 SG_ SECOND_PARAMETER_VALUE : 32|32@1+ (1,0) [0|0] "" Vector__XXX

CM_ BO_ 2181386432 "Read parameter 166 and 167 at the same time. SPARK MAX does not currently support this in v25.0.0-prerelease.4";
CM_ SG_ 2181386432 FIRST_PARAMETER_VALUE "The actual type of this data depends on the Parameter Type of the parameter in question";
CM_ SG_ 2181386432 SECOND_PARAMETER_VALUE "The actual type of this data depends on the Parameter Type of the parameter in question";

BO_ 2181386496 READ_PARAMETER_168_AND_169: 8 Vector__XXX
 SG_ FIRST_PARAMETER_VALUE : 0|32@1+ (1,0) [0|0] "" Vector__XXX
 SG_ SECOND_PARAMETER_VALUE : 32|32@1+ (1,0) [0|0] "" Vector__XXX

CM_ BO_ 2181386496 "Read parameter 168 and 169 at the same time. SPARK MAX does not currently support this in v25.0.0-prerelease.4";
CM_ SG_ 2181386496 FIRST_PARAMETER_VALUE "The actual type of this data depends on the Parameter Type of the parameter in question";
CM_ SG_ 2181386496 SECOND_PARAMETER_VALUE "The actual type of this data depends on the Parameter Type of the parameter in question";

BO_ 2181386560 READ_PARAMETER_170_AND_171: 8 Vector__XXX
 SG_ FIRST_PARAMETER_VALUE : 0|32@1+ (1,0) [0|0] "" Vector__XXX
 SG_ SECOND_PARAMETER_VALUE : 32|32@1+ (1,0) [0|0] "" Vector__XXX

CM_ BO_ 2181386560 "Read parameter 170 and 171 at the same time. SPARK MAX does not currently support this in v25.0.0-prerelease.4";
CM_ SG_ 2181386560 FIRST_PARAMETER_VALUE "The actual type of this data depends on the Parameter Type of the parameter in question";
CM_ SG_ 2181386560 SECOND_PARAMETER_VALUE "The actual type of this data depends on the Parameter Type of the parameter in question";

BO_ 2181386624 READ_PARAMETER_172_AND_173: 8 Vector__XXX
 SG_ FIRST_PARAMETER_VALUE : 0|32@1+ (1,0) [0|0] "" Vector__XXX
 SG_ SECOND_PARAMETER_VALUE : 32|32@1+ (1,0) [0|0] "" Vector__XXX

CM_ BO_ 2181386624 "Read parameter 172 and 173 at the same time. SPARK MAX does not currently support this in v25.0.0-prerelease.4";
CM_ SG_ 2181386624 FIRST_PARAMETER_VALUE "The actual type of this data depends on the Parameter Type of the parameter in question";
CM_ SG_ 2181386624 SECOND_PARAMETER_VALUE "The actual type of this data depends on the Parameter Type of the parameter in question";

BO_ 2181386688 READ_PARAMETER_174_AND_175: 8 Vector__XXX
 SG_ FIRST_PARAMETER_VALUE : 0|32@1+ (1,0) [0|0] "" Vector__XXX
 SG_ SECOND_PARAMETER_VALUE : 32|32@1+ (1,0) [0|0] "" Vector__XXX

CM_ BO_ 2181386688 "Read parameter 174 and 175 at the same time. SPARK MAX does not currently support this in v25.0.0-prerelease.4";
CM_ SG_ 2181386688 FIRST_PARAMETER_VALUE "The actual type of this data depends on the Parameter Type of the parameter in question";
CM_ SG_ 2181386688 SECOND_PARAMETER_VALUE "The actual type of this data depends on the Parameter Type of the parameter in question";

BO_ 2181386752 READ_PARAMETER_176_AND_177: 8 Vector__XXX
 SG_ FIRST_PARAMETER_VALUE : 0|32@1+ (1,0) [0|0] "" Vector__XXX
 SG_ SECOND_PARAMETER_VALUE : 32|32@1+ (1,0) [0|0] "" Vector__XXX

CM_ BO_ 2181386752 "Read parameter 176 and 177 at the same time. SPARK MAX does not currently support this in v25.0.0-prerelease.4";
CM_ SG_ 2181386752 FIRST_PARAMETER_VALUE "The actual type of this data depends on the Parameter Type of the parameter in question";
CM_ SG_ 2181386752 SECOND_PARAMETER_VALUE "The actual type of this data depends on the Parameter Type of the parameter in question";

BO_ 2181386816 READ_PARAMETER_178_AND_179: 8 Vector__XXX
 SG_ FIRST_PARAMETER_VALUE : 0|32@1+ (1,0) [0|0] "" Vector__XXX
 SG_ SECOND_PARAMETER_VALUE : 32|32@1+ (1,0) [0|0] "" Vector__XXX

CM_ BO_ 2181386816 "Read parameter 178 and 179 at the same time. SPARK MAX does not currently support this in v25.0.0-prerelease.4";
CM_ SG_ 2181386816 FIRST_PARAMETER_VALUE "The actual type of this data depends on the Parameter Type of the parameter in question";
CM_ SG_ 2181386816 SECOND_PARAMETER_VALUE "The actual type of this data depends on the Parameter Type of the parameter in question";

BO_ 2181386880 READ_PARAMETER_180_AND_181: 8 Vector__XXX
 SG_ FIRST_PARAMETER_VALUE : 0|32@1+ (1,0) [0|0] "" Vector__XXX
 SG_ SECOND_PARAMETER_VALUE : 32|32@1+ (1,0) [0|0] "" Vector__XXX

CM_ BO_ 2181386880 "Read parameter 180 and 181 at the same time. SPARK MAX does not currently support this in v25.0.0-prerelease.4";
CM_ SG_ 2181386880 FIRST_PARAMETER_VALUE "The actual type of this data depends on the Parameter Type of the parameter in question";
CM_ SG_ 2181386880 SECOND_PARAMETER_VALUE "The actual type of this data depends on the Parameter Type of the parameter in question";

BO_ 2181386944 READ_PARAMETER_182_AND_183: 8 Vector__XXX
 SG_ FIRST_PARAMETER_VALUE : 0|32@1+ (1,0) [0|0] "" Vector__XXX
 SG_ SECOND_PARAMETER_VALUE : 32|32@1+ (1,0) [0|0] "" Vector__XXX

CM_ BO_ 2181386944 "Read parameter 182 and 183 at the same time. SPARK MAX does not currently support this in v25.0.0-prerelease.4";
CM_ SG_ 2181386944 FIRST_PARAMETER_VALUE "The actual type of this data depends on the Parameter Type of the parameter in question";
CM_ SG_ 2181386944 SECOND_PARAMETER_VALUE "The actual type of this data depends on the Parameter Type of the parameter in question";

BO_ 2181387008 READ_PARAMETER_184_AND_185: 8 Vector__XXX
 SG_ FIRST_PARAMETER_VALUE : 0|32@1+ (1,0) [0|0] "" Vector__XXX
 SG_ SECOND_PARAMETER_VALUE : 32|32@1+ (1,0) [0|0] "" Vector__XXX

CM_ BO_ 2181387008 "Read parameter 184 and 185 at the same time. SPARK MAX does not currently support this in v25.0.0-prerelease.4";
CM_ SG_ 2181387008 FIRST_PARAMETER_VALUE "The actual type of this data depends on the Parameter Type of the parameter in question";
CM_ SG_ 2181387008 SECOND_PARAMETER_VALUE "The actual type of this data depends on the Parameter Type of the parameter in question";

BO_ 2181387072 READ_PARAMETER_186_AND_187: 8 Vector__XXX
 SG_ FIRST_PARAMETER_VALUE : 0|32@1+ (1,0) [0|0] "" Vector__XXX
 SG_ SECOND_PARAMETER_VALUE : 32|32@1+ (1,0) [0|0] "" Vector__XXX

CM_ BO_ 2181387072 "Read parameter 186 and 187 at the same time. SPARK MAX does not currently support this in v25.0.0-prerelease.4";
CM_ SG_ 2181387072 FIRST_PARAMETER_VALUE "The actual type of this data depends on the Parameter Type of the parameter in question";
CM_ SG_ 2181387072 SECOND_PARAMETER_VALUE "The actual type of this data depends on the Parameter Type of the parameter in question";

BO_ 2181387136 READ_PARAMETER_188_AND_189: 8 Vector__XXX
 SG_ FIRST_PARAMETER_VALUE : 0|32@1+ (1,0) [0|0] "" Vector__XXX
 SG_ SECOND_PARAMETER_VALUE : 32|32@1+ (1,0) [0|0] "" Vector__XXX

CM_ BO_ 2181387136 "Read parameter 188 and 189 at the same time. SPARK MAX does not currently support this in v25.0.0-prerelease.4";
CM_ SG_ 2181387136 FIRST_PARAMETER_VALUE "The actual type of this data depends on the Parameter Type of the parameter in question";
CM_ SG_ 2181387136 SECOND_PARAMETER_VALUE "The actual type of this data depends on the Parameter Type of the parameter in question";

BO_ 2181387200 READ_PARAMETER_190_AND_191: 8 Vector__XXX
 SG_ FIRST_PARAMETER_VALUE : 0|32@1+ (1,0) [0|0] "" Vector__XXX
 SG_ SECOND_PARAMETER_VALUE : 32|32@1+ (1,0) [0|0] "" Vector__XXX

CM_ BO_ 2181387200 "Read parameter 190 and 191 at the same time. SPARK MAX does not currently support this in v25.0.0-prerelease.4";
CM_ SG_ 2181387200 FIRST_PARAMETER_VALUE "The actual type of this data depends on the Parameter Type of the parameter in question";
CM_ SG_ 2181387200 SECOND_PARAMETER_VALUE "The actual type of this data depends on the Parameter Type of the parameter in question";
